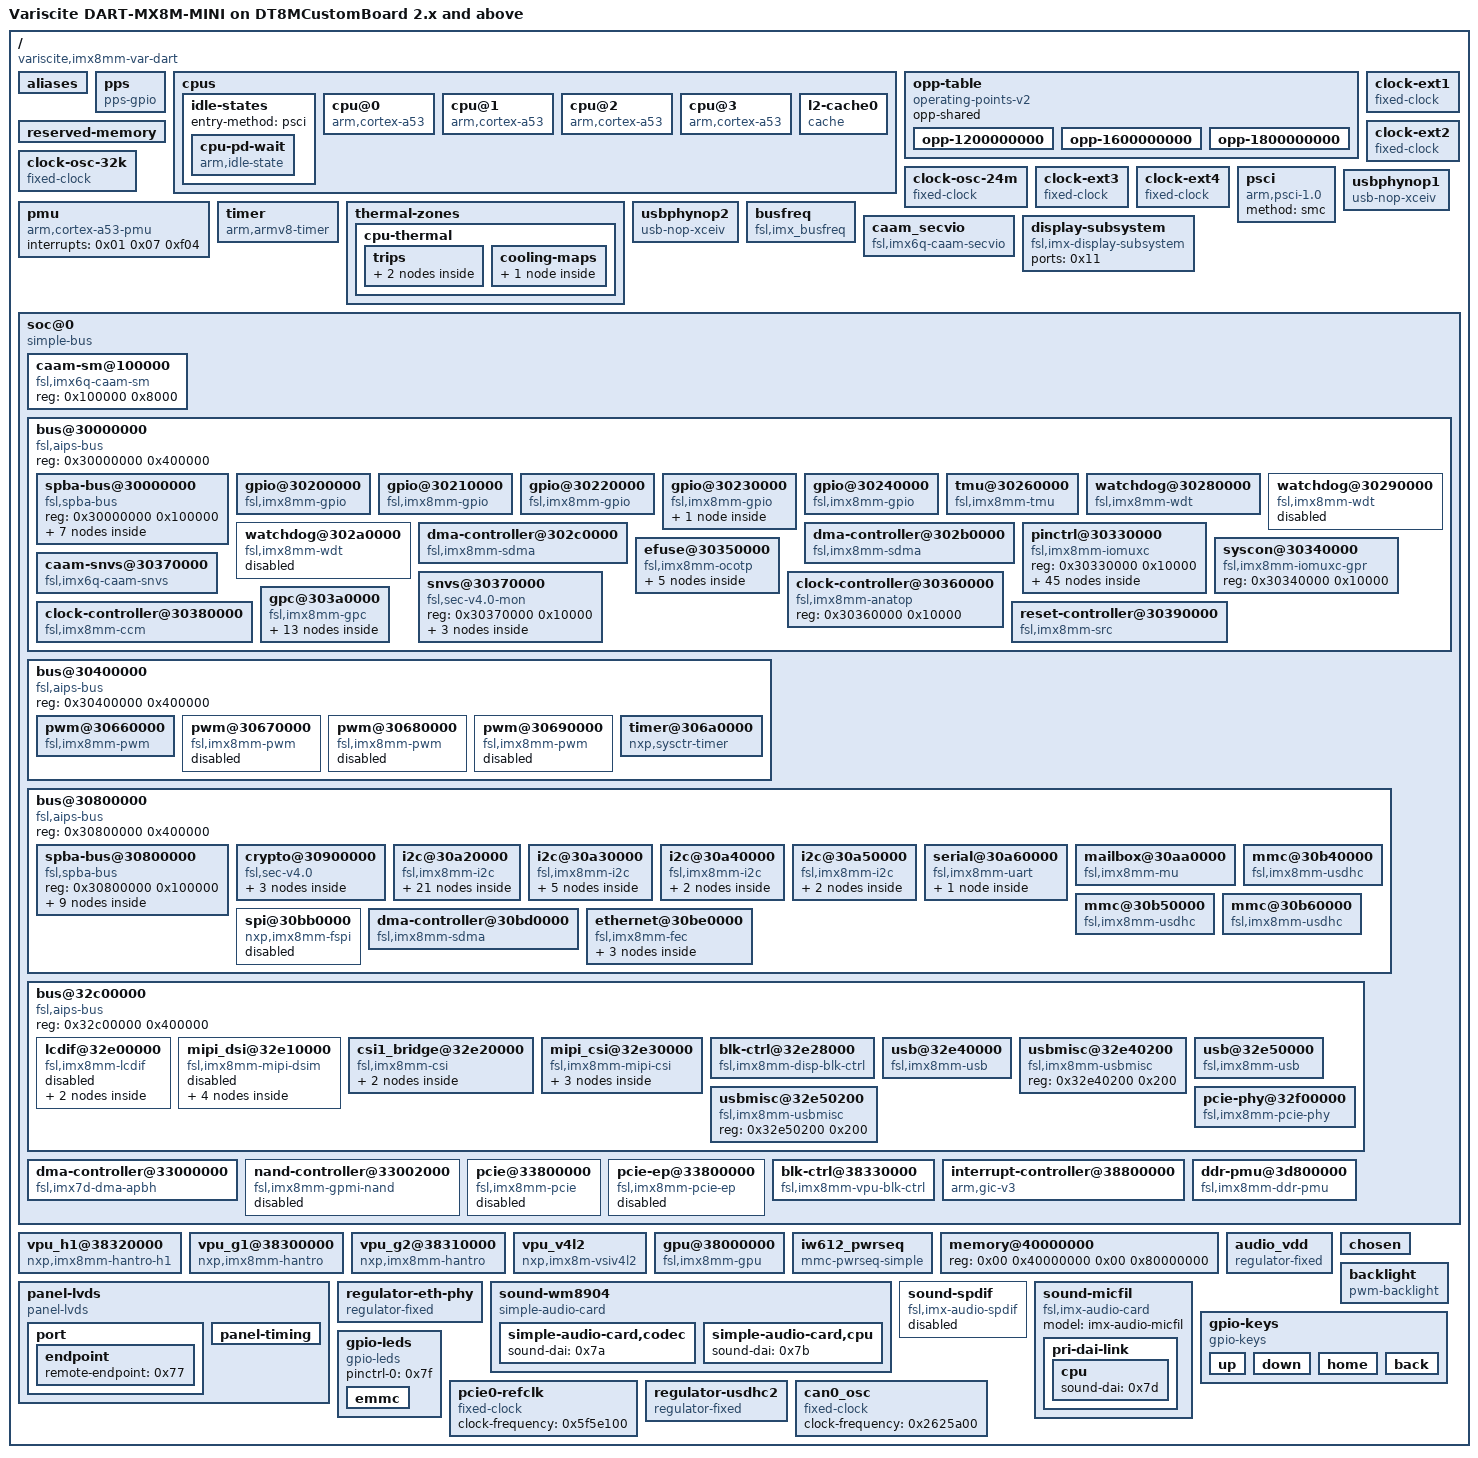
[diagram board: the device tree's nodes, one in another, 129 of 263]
/dts-v1/;

/ {
	interrupt-parent = <0x01>;
	#address-cells = <0x02>;
	#size-cells = <0x02>;
	compatible = "variscite,imx8mm-var-dart\0fsl,imx8mm";
	model = "Variscite DART-MX8M-MINI on DT8MCustomBoard 2.x and above";
	p1-version = "v1.0";

	aliases {
		ethernet0 = "/soc@0/bus@30800000/ethernet@30be0000";
		gpio0 = "/soc@0/bus@30000000/gpio@30200000";
		gpio1 = "/soc@0/bus@30000000/gpio@30210000";
		gpio2 = "/soc@0/bus@30000000/gpio@30220000";
		gpio3 = "/soc@0/bus@30000000/gpio@30230000";
		gpio4 = "/soc@0/bus@30000000/gpio@30240000";
		i2c0 = "/soc@0/bus@30800000/i2c@30a20000";
		i2c1 = "/soc@0/bus@30800000/i2c@30a30000";
		i2c2 = "/soc@0/bus@30800000/i2c@30a40000";
		i2c3 = "/soc@0/bus@30800000/i2c@30a50000";
		mmc0 = "/soc@0/bus@30800000/mmc@30b40000";
		mmc1 = "/soc@0/bus@30800000/mmc@30b50000";
		mmc2 = "/soc@0/bus@30800000/mmc@30b60000";
		sai1 = "/soc@0/bus@30000000/spba-bus@30000000/sai@30010000";
		sai2 = "/soc@0/bus@30000000/spba-bus@30000000/sai@30020000";
		sai3 = "/soc@0/bus@30000000/spba-bus@30000000/sai@30030000";
		sai5 = "/soc@0/bus@30000000/spba-bus@30000000/sai@30050000";
		sai6 = "/soc@0/bus@30000000/spba-bus@30000000/sai@30060000";
		serial0 = "/soc@0/bus@30800000/spba-bus@30800000/serial@30860000";
		serial1 = "/soc@0/bus@30800000/spba-bus@30800000/serial@30890000";
		serial2 = "/soc@0/bus@30800000/spba-bus@30800000/serial@30880000";
		serial3 = "/soc@0/bus@30800000/serial@30a60000";
		spi0 = "/soc@0/bus@30800000/spba-bus@30800000/spi@30820000";
		spi1 = "/soc@0/bus@30800000/spba-bus@30800000/spi@30830000";
		spi2 = "/soc@0/bus@30800000/spba-bus@30800000/spi@30840000";
	};

	pps {
		pinctrl-names = "default";
		pinctrl-0 = <0xd5>;
		compatible = "pps-gpio";
		gpios = <0x29 0x06 0x00>;
		status = "okay";
	};

	cpus {
		#address-cells = <0x01>;
		#size-cells = <0x00>;

		idle-states {
			entry-method = "psci";

			cpu-pd-wait {
				compatible = "arm,idle-state";
				arm,psci-suspend-param = <0x10033>;
				local-timer-stop;
				entry-latency-us = <0x3e8>;
				exit-latency-us = <0x2bc>;
				min-residency-us = <0xa8c>;
				phandle = <0x06>;
			};
		};

		cpu@0 {
			device_type = "cpu";
			compatible = "arm,cortex-a53";
			reg = <0x00>;
			clock-latency = <0xee6c>;
			clocks = <0x02 0xd7>;
			enable-method = "psci";
			i-cache-size = <0x8000>;
			i-cache-line-size = <0x40>;
			i-cache-sets = <0x100>;
			d-cache-size = <0x8000>;
			d-cache-line-size = <0x40>;
			d-cache-sets = <0x80>;
			next-level-cache = <0x03>;
			operating-points-v2 = <0x04>;
			nvmem-cells = <0x05>;
			nvmem-cell-names = "speed_grade";
			cpu-idle-states = <0x06>;
			#cooling-cells = <0x02>;
			cpu-supply = <0x07>;
			phandle = <0x0a>;
		};

		cpu@1 {
			device_type = "cpu";
			compatible = "arm,cortex-a53";
			reg = <0x01>;
			clock-latency = <0xee6c>;
			clocks = <0x02 0xd7>;
			enable-method = "psci";
			i-cache-size = <0x8000>;
			i-cache-line-size = <0x40>;
			i-cache-sets = <0x100>;
			d-cache-size = <0x8000>;
			d-cache-line-size = <0x40>;
			d-cache-sets = <0x80>;
			next-level-cache = <0x03>;
			operating-points-v2 = <0x04>;
			cpu-idle-states = <0x06>;
			#cooling-cells = <0x02>;
			cpu-supply = <0x07>;
			phandle = <0x0b>;
		};

		cpu@2 {
			device_type = "cpu";
			compatible = "arm,cortex-a53";
			reg = <0x02>;
			clock-latency = <0xee6c>;
			clocks = <0x02 0xd7>;
			enable-method = "psci";
			i-cache-size = <0x8000>;
			i-cache-line-size = <0x40>;
			i-cache-sets = <0x100>;
			d-cache-size = <0x8000>;
			d-cache-line-size = <0x40>;
			d-cache-sets = <0x80>;
			next-level-cache = <0x03>;
			operating-points-v2 = <0x04>;
			cpu-idle-states = <0x06>;
			#cooling-cells = <0x02>;
			cpu-supply = <0x07>;
			phandle = <0x0c>;
		};

		cpu@3 {
			device_type = "cpu";
			compatible = "arm,cortex-a53";
			reg = <0x03>;
			clock-latency = <0xee6c>;
			clocks = <0x02 0xd7>;
			enable-method = "psci";
			i-cache-size = <0x8000>;
			i-cache-line-size = <0x40>;
			i-cache-sets = <0x100>;
			d-cache-size = <0x8000>;
			d-cache-line-size = <0x40>;
			d-cache-sets = <0x80>;
			next-level-cache = <0x03>;
			operating-points-v2 = <0x04>;
			cpu-idle-states = <0x06>;
			#cooling-cells = <0x02>;
			cpu-supply = <0x07>;
			phandle = <0x0d>;
		};

		l2-cache0 {
			compatible = "cache";
			cache-level = <0x02>;
			cache-unified;
			cache-size = <0x80000>;
			cache-line-size = <0x40>;
			cache-sets = <0x200>;
			phandle = <0x03>;
		};
	};

	opp-table {
		compatible = "operating-points-v2";
		opp-shared;
		phandle = <0x04>;

		opp-1200000000 {
			opp-hz = <0x00 0x47868c00>;
			opp-microvolt = <0xcf850>;
			opp-supported-hw = <0x0e 0x07>;
			clock-latency-ns = <0x249f0>;
			opp-suspend;
		};

		opp-1600000000 {
			opp-hz = <0x00 0x5f5e1000>;
			opp-microvolt = <0xe7ef0>;
			opp-supported-hw = <0x0c 0x07>;
			clock-latency-ns = <0x249f0>;
			opp-suspend;
		};

		opp-1800000000 {
			opp-hz = <0x00 0x6b49d200>;
			opp-microvolt = <0xf4240>;
			opp-supported-hw = <0x08 0x03>;
			clock-latency-ns = <0x249f0>;
			opp-suspend;
		};
	};

	reserved-memory {
		#address-cells = <0x02>;
		#size-cells = <0x02>;
		ranges;
		phandle = <0x81>;
	};

	clock-osc-32k {
		compatible = "fixed-clock";
		#clock-cells = <0x00>;
		clock-frequency = <0x8000>;
		clock-output-names = "osc_32k";
		phandle = <0x1c>;
	};

	clock-osc-24m {
		compatible = "fixed-clock";
		#clock-cells = <0x00>;
		clock-frequency = <0x16e3600>;
		clock-output-names = "osc_24m";
		phandle = <0x1d>;
	};

	clock-ext1 {
		compatible = "fixed-clock";
		#clock-cells = <0x00>;
		clock-frequency = <0x7ed6b40>;
		clock-output-names = "clk_ext1";
		phandle = <0x1e>;
	};

	clock-ext2 {
		compatible = "fixed-clock";
		#clock-cells = <0x00>;
		clock-frequency = <0x7ed6b40>;
		clock-output-names = "clk_ext2";
		phandle = <0x1f>;
	};

	clock-ext3 {
		compatible = "fixed-clock";
		#clock-cells = <0x00>;
		clock-frequency = <0x7ed6b40>;
		clock-output-names = "clk_ext3";
		phandle = <0x20>;
	};

	clock-ext4 {
		compatible = "fixed-clock";
		#clock-cells = <0x00>;
		clock-frequency = <0x7ed6b40>;
		clock-output-names = "clk_ext4";
		phandle = <0x21>;
	};

	psci {
		compatible = "arm,psci-1.0";
		method = "smc";
	};

	pmu {
		compatible = "arm,cortex-a53-pmu";
		interrupts = <0x01 0x07 0xf04>;
	};

	timer {
		compatible = "arm,armv8-timer";
		interrupts = <0x01 0x0d 0xf08 0x01 0x0e 0xf08 0x01 0x0b 0xf08 0x01 0x0a 0xf08>;
		clock-frequency = <0x7a1200>;
		arm,no-tick-in-suspend;
	};

	thermal-zones {

		cpu-thermal {
			polling-delay-passive = <0xfa>;
			polling-delay = <0x7d0>;
			thermal-sensors = <0x08>;

			trips {

				trip0 {
					temperature = <0x14c08>;
					hysteresis = <0x7d0>;
					type = "passive";
					phandle = <0x09>;
				};

				trip1 {
					temperature = <0x17318>;
					hysteresis = <0x7d0>;
					type = "critical";
					phandle = <0x82>;
				};
			};

			cooling-maps {

				map0 {
					trip = <0x09>;
					cooling-device = <0x0a 0xffffffff 0xffffffff 0x0b 0xffffffff 0xffffffff 0x0c 0xffffffff 0xffffffff 0x0d 0xffffffff 0xffffffff 0x0e 0x00 0x01>;
				};
			};
		};
	};

	usbphynop1 {
		#phy-cells = <0x00>;
		compatible = "usb-nop-xceiv";
		clocks = <0x02 0x84>;
		assigned-clocks = <0x02 0x84>;
		assigned-clock-parents = <0x02 0x32>;
		clock-names = "main_clk";
		power-domains = <0x0f>;
		wakeup-source;
		phandle = <0x67>;
	};

	usbphynop2 {
		#phy-cells = <0x00>;
		compatible = "usb-nop-xceiv";
		clocks = <0x02 0x84>;
		assigned-clocks = <0x02 0x84>;
		assigned-clock-parents = <0x02 0x32>;
		clock-names = "main_clk";
		power-domains = <0x10>;
		wakeup-source;
		phandle = <0x6a>;
	};

	busfreq {
		compatible = "fsl,imx_busfreq";
		clocks = <0x02 0x29 0x02 0x61 0x02 0x62 0x02 0x62 0x02 0xdc 0x02 0xdd 0x02 0x30 0x02 0x32 0x02 0x3f 0x02 0x5b 0x02 0x5d 0x02 0x51 0x02 0x02 0x02 0x38 0x02 0x15>;
		clock-names = "dram_pll\0dram_alt_src\0dram_apb_src\0dram_apb_pre_div\0dram_core\0dram_alt_root\0sys_pll1_40m\0sys_pll1_100m\0sys_pll2_333m\0noc_div\0ahb_div\0main_axi_src\0osc_24m\0sys_pll1_800m\0dram_pll_div";
		interrupts = <0x00 0x4a 0x04 0x00 0x4b 0x04 0x00 0x4c 0x04 0x00 0x4d 0x04>;
		interrupt-name = "irq_busfreq_0\0irq_busfreq_1\0irq_busfreq_2\0irq_busfreq_3";
	};

	caam_secvio {
		compatible = "fsl,imx6q-caam-secvio";
		interrupts = <0x00 0x14 0x04>;
		jtag-tamper = "disabled";
		watchdog-tamper = "enabled";
		internal-boot-tamper = "enabled";
		external-pin-tamper = "disabled";
		phandle = <0x83>;
	};

	display-subsystem {
		compatible = "fsl,imx-display-subsystem";
		ports = <0x11>;
	};

	soc@0 {
		compatible = "simple-bus";
		#address-cells = <0x01>;
		#size-cells = <0x01>;
		ranges = <0x00 0x00 0x00 0x3e000000>;
		dma-ranges = <0x40000000 0x00 0x40000000 0xc0000000>;
		nvmem-cells = <0x12>;
		nvmem-cell-names = "soc_unique_id";
		phandle = <0x84>;

		caam-sm@100000 {
			compatible = "fsl,imx6q-caam-sm";
			reg = <0x100000 0x8000>;
			phandle = <0x85>;
		};

		bus@30000000 {
			compatible = "fsl,aips-bus\0simple-bus";
			reg = <0x30000000 0x400000>;
			#address-cells = <0x01>;
			#size-cells = <0x01>;
			ranges = <0x30000000 0x30000000 0x400000>;
			phandle = <0x86>;

			spba-bus@30000000 {
				compatible = "fsl,spba-bus\0simple-bus";
				#address-cells = <0x01>;
				#size-cells = <0x01>;
				reg = <0x30000000 0x100000>;
				ranges;
				phandle = <0x87>;

				sai@30010000 {
					#sound-dai-cells = <0x00>;
					compatible = "fsl,imx8mm-sai\0fsl,imx8mq-sai";
					reg = <0x30010000 0x10000>;
					interrupts = <0x00 0x5f 0x04>;
					clocks = <0x02 0xb1 0x02 0x00 0x02 0xb0 0x02 0x00 0x02 0x00>;
					clock-names = "bus\0mclk0\0mclk1\0mclk2\0mclk3";
					dmas = <0x13 0x00 0x02 0x00 0x13 0x01 0x02 0x00>;
					dma-names = "rx\0tx";
					fsl,dataline = <0x00 0xff 0xff>;
					status = "disabled";
					phandle = <0x88>;
				};

				sai@30020000 {
					#sound-dai-cells = <0x00>;
					compatible = "fsl,imx8mm-sai\0fsl,imx8mq-sai";
					reg = <0x30020000 0x10000>;
					interrupts = <0x00 0x60 0x04>;
					clocks = <0x02 0xb3 0x02 0x00 0x02 0xb2 0x02 0x00 0x02 0x00>;
					clock-names = "bus\0mclk0\0mclk1\0mclk2\0mclk3";
					dmas = <0x13 0x02 0x02 0x00 0x13 0x03 0x02 0x00>;
					dma-names = "rx\0tx";
					status = "disabled";
					phandle = <0x89>;
				};

				sai@30030000 {
					#sound-dai-cells = <0x00>;
					compatible = "fsl,imx8mm-sai\0fsl,imx8mq-sai";
					reg = <0x30030000 0x10000>;
					interrupts = <0x00 0x32 0x04>;
					clocks = <0x02 0xb5 0x02 0x00 0x02 0xb4 0x02 0x00 0x02 0x00>;
					clock-names = "bus\0mclk0\0mclk1\0mclk2\0mclk3";
					dmas = <0x13 0x04 0x02 0x00 0x13 0x05 0x02 0x00>;
					dma-names = "rx\0tx";
					status = "okay";
					pinctrl-names = "default";
					pinctrl-0 = <0x14>;
					assigned-clocks = <0x02 0x6e>;
					assigned-clock-parents = <0x02 0x26>;
					assigned-clock-rates = <0x177000>;
					fsl,sai-mclk-direction-output;
					fsl,sai-synchronous-rx;
					phandle = <0x7b>;
				};

				sai@30050000 {
					#sound-dai-cells = <0x00>;
					compatible = "fsl,imx8mm-sai\0fsl,imx8mq-sai";
					reg = <0x30050000 0x10000>;
					interrupts = <0x00 0x5a 0x04>;
					clocks = <0x02 0xb9 0x02 0x00 0x02 0xb8 0x02 0x00 0x02 0x00>;
					clock-names = "bus\0mclk0\0mclk1\0mclk2\0mclk3";
					dmas = <0x13 0x08 0x02 0x00 0x13 0x09 0x02 0x00>;
					dma-names = "rx\0tx";
					fsl,dataline = <0x00 0x0f 0x0f>;
					status = "disabled";
					phandle = <0x8a>;
				};

				sai@30060000 {
					#sound-dai-cells = <0x00>;
					compatible = "fsl,imx8mm-sai\0fsl,imx8mq-sai";
					reg = <0x30060000 0x10000>;
					interrupts = <0x00 0x5a 0x04>;
					clocks = <0x02 0xbb 0x02 0x00 0x02 0xba 0x02 0x00 0x02 0x00>;
					clock-names = "bus\0mclk0\0mclk1\0mclk2\0mclk3";
					dmas = <0x13 0x0a 0x02 0x00 0x13 0x0b 0x02 0x00>;
					dma-names = "rx\0tx";
					status = "disabled";
					phandle = <0x8b>;
				};

				audio-controller@30080000 {
					compatible = "fsl,imx8mm-micfil";
					reg = <0x30080000 0x10000>;
					interrupts = <0x00 0x6d 0x04 0x00 0x6e 0x04 0x00 0x2c 0x04 0x00 0x2d 0x04>;
					clocks = <0x02 0xd8 0x02 0xcb 0x02 0x26 0x02 0x27 0x02 0x06>;
					clock-names = "ipg_clk\0ipg_clk_app\0pll8k\0pll11k\0clkext3";
					dmas = <0x13 0x18 0x19 0x80000000>;
					dma-names = "rx";
					#sound-dai-cells = <0x00>;
					status = "disabled";
					pinctrl-names = "default";
					pinctrl-0 = <0x15>;
					assigned-clocks = <0x02 0x9c>;
					assigned-clock-parents = <0x02 0x26>;
					assigned-clock-rates = <0xbb80000>;
					phandle = <0x7d>;
				};

				spdif@30090000 {
					compatible = "fsl,imx35-spdif";
					reg = <0x30090000 0x10000>;
					interrupts = <0x00 0x06 0x04>;
					clocks = <0x02 0x5e 0x02 0x02 0x02 0x72 0x02 0x00 0x02 0x00 0x02 0x00 0x02 0x5e 0x02 0x00 0x02 0x00 0x02 0x00 0x02 0x26 0x02 0x27>;
					clock-names = "core\0rxtx0\0rxtx1\0rxtx2\0rxtx3\0rxtx4\0rxtx5\0rxtx6\0rxtx7\0spba\0pll8k\0pll11k";
					dmas = <0x13 0x1c 0x12 0x00 0x13 0x1d 0x12 0x00>;
					dma-names = "rx\0tx";
					status = "disabled";
					pinctrl-names = "default";
					pinctrl-0 = <0x16>;
					assigned-clocks = <0x02 0x72>;
					assigned-clock-parents = <0x02 0x26>;
					assigned-clock-rates = <0x1770000>;
					phandle = <0x7c>;
				};
			};

			gpio@30200000 {
				compatible = "fsl,imx8mm-gpio\0fsl,imx35-gpio";
				reg = <0x30200000 0x10000>;
				interrupts = <0x00 0x40 0x04 0x00 0x41 0x04>;
				clocks = <0x02 0xdf>;
				gpio-controller;
				#gpio-cells = <0x02>;
				interrupt-controller;
				#interrupt-cells = <0x02>;
				gpio-ranges = <0x17 0x00 0x0a 0x1e>;
				phandle = <0x29>;
			};

			gpio@30210000 {
				compatible = "fsl,imx8mm-gpio\0fsl,imx35-gpio";
				reg = <0x30210000 0x10000>;
				interrupts = <0x00 0x42 0x04 0x00 0x43 0x04>;
				clocks = <0x02 0xe0>;
				gpio-controller;
				#gpio-cells = <0x02>;
				interrupt-controller;
				#interrupt-cells = <0x02>;
				gpio-ranges = <0x17 0x00 0x28 0x15>;
				phandle = <0x32>;
			};

			gpio@30220000 {
				compatible = "fsl,imx8mm-gpio\0fsl,imx35-gpio";
				reg = <0x30220000 0x10000>;
				interrupts = <0x00 0x44 0x04 0x00 0x45 0x04>;
				clocks = <0x02 0xe1>;
				gpio-controller;
				#gpio-cells = <0x02>;
				interrupt-controller;
				#interrupt-cells = <0x02>;
				gpio-ranges = <0x17 0x00 0x3d 0x1a>;
				phandle = <0x8c>;
			};

			gpio@30230000 {
				compatible = "fsl,imx8mm-gpio\0fsl,imx35-gpio";
				reg = <0x30230000 0x10000>;
				interrupts = <0x00 0x46 0x04 0x00 0x47 0x04>;
				clocks = <0x02 0xe2>;
				gpio-controller;
				#gpio-cells = <0x02>;
				interrupt-controller;
				#interrupt-cells = <0x02>;
				gpio-ranges = <0x17 0x00 0x57 0x20>;
				pinctrl-names = "default";
				pinctrl-0 = <0x18>;
				phandle = <0x2a>;

				sec_rstn {
					gpio-hog;
					gpios = <0x1f 0x00>;
					output-high;
					line-name = "sec_rstn";
				};
			};

			gpio@30240000 {
				compatible = "fsl,imx8mm-gpio\0fsl,imx35-gpio";
				reg = <0x30240000 0x10000>;
				interrupts = <0x00 0x48 0x04 0x00 0x49 0x04>;
				clocks = <0x02 0xe3>;
				gpio-controller;
				#gpio-cells = <0x02>;
				interrupt-controller;
				#interrupt-cells = <0x02>;
				gpio-ranges = <0x17 0x00 0x77 0x1e>;
				phandle = <0x28>;
			};

			tmu@30260000 {
				compatible = "fsl,imx8mm-tmu";
				reg = <0x30260000 0x10000>;
				clocks = <0x02 0xd1>;
				nvmem-cells = <0x19>;
				nvmem-cell-names = "calib";
				#thermal-sensor-cells = <0x00>;
				phandle = <0x08>;
			};

			watchdog@30280000 {
				compatible = "fsl,imx8mm-wdt\0fsl,imx21-wdt";
				reg = <0x30280000 0x10000>;
				interrupts = <0x00 0x4e 0x04>;
				clocks = <0x02 0xc4>;
				status = "okay";
				pinctrl-names = "default";
				pinctrl-0 = <0x1a>;
				fsl,ext-reset-output;
				phandle = <0x8d>;
			};

			watchdog@30290000 {
				compatible = "fsl,imx8mm-wdt\0fsl,imx21-wdt";
				reg = <0x30290000 0x10000>;
				interrupts = <0x00 0x4f 0x04>;
				clocks = <0x02 0xc5>;
				status = "disabled";
				phandle = <0x8e>;
			};

			watchdog@302a0000 {
				compatible = "fsl,imx8mm-wdt\0fsl,imx21-wdt";
				reg = <0x302a0000 0x10000>;
				interrupts = <0x00 0x0a 0x04>;
				clocks = <0x02 0xc6>;
				status = "disabled";
				phandle = <0x8f>;
			};

			dma-controller@302c0000 {
				compatible = "fsl,imx8mm-sdma\0fsl,imx8mq-sdma";
				reg = <0x302c0000 0x10000>;
				interrupts = <0x00 0x67 0x04>;
				clocks = <0x02 0xd4 0x02 0xd4>;
				clock-names = "ipg\0ahb";
				#dma-cells = <0x03>;
				fsl,sdma-ram-script-name = "imx/sdma/sdma-imx7d.bin";
				phandle = <0x13>;
			};

			dma-controller@302b0000 {
				compatible = "fsl,imx8mm-sdma\0fsl,imx8mq-sdma";
				reg = <0x302b0000 0x10000>;
				interrupts = <0x00 0x22 0x04>;
				clocks = <0x02 0xd5 0x02 0xd5>;
				clock-names = "ipg\0ahb";
				#dma-cells = <0x03>;
				fsl,sdma-ram-script-name = "imx/sdma/sdma-imx7d.bin";
				phandle = <0x90>;
			};

			pinctrl@30330000 {
				compatible = "fsl,imx8mm-iomuxc";
				reg = <0x30330000 0x10000>;
				phandle = <0x17>;

				fec1grp {
					fsl,pins = <0x68 0x2d0 0x00 0x00 0x00 0x03 0x6c 0x2d4 0x4c0 0x00 0x01 0x03 0x70 0x2d8 0x00 0x00 0x00 0x1f 0x74 0x2dc 0x00 0x00 0x00 0x1f 0x78 0x2e0 0x00 0x00 0x00 0x1f 0x7c 0x2e4 0x00 0x00 0x00 0x1f 0x9c 0x304 0x00 0x00 0x00 0x91 0x98 0x300 0x00 0x00 0x00 0x91 0x94 0x2fc 0x00 0x00 0x00 0x91 0x90 0x2f8 0x00 0x00 0x00 0x91 0x84 0x2ec 0x00 0x00 0x00 0x1f 0x8c 0x2f4 0x00 0x00 0x00 0x91 0x88 0x2f0 0x00 0x00 0x00 0x91 0x80 0x2e8 0x00 0x00 0x00 0x1f 0x4c 0x2b4 0x00 0x00 0x00 0x19>;
					phandle = <0x59>;
				};

				fec1grpsleep {
					fsl,pins = <0x68 0x2d0 0x00 0x05 0x00 0x120 0x6c 0x2d4 0x00 0x05 0x00 0x120 0x70 0x2d8 0x00 0x05 0x00 0x120 0x74 0x2dc 0x00 0x05 0x00 0x120 0x78 0x2e0 0x00 0x05 0x00 0x120 0x7c 0x2e4 0x00 0x05 0x00 0x120 0x9c 0x304 0x00 0x05 0x00 0x120 0x98 0x300 0x00 0x05 0x00 0x120 0x94 0x2fc 0x00 0x05 0x00 0x120 0x90 0x2f8 0x00 0x05 0x00 0x120 0x84 0x2ec 0x00 0x05 0x00 0x120 0x8c 0x2f4 0x00 0x05 0x00 0x120 0x88 0x2f0 0x00 0x05 0x00 0x120 0x80 0x2e8 0x00 0x05 0x00 0x120 0x4c 0x2b4 0x00 0x00 0x00 0x100>;
					phandle = <0x5a>;
				};

				i2c1grp {
					fsl,pins = <0x214 0x47c 0x00 0x00 0x00 0x400001c3 0x218 0x480 0x00 0x00 0x00 0x400001c3>;
					phandle = <0x30>;
				};

				tpm-resetgrp {
					fsl,pins = <0x1d8 0x440 0x00 0x05 0x00 0x19>;
					phandle = <0x18>;
				};

				i2c3grp {
					fsl,pins = <0x224 0x48c 0x00 0x00 0x00 0x400001c3 0x228 0x490 0x00 0x00 0x00 0x400001c3>;
					phandle = <0x40>;
				};

				i2c1grp-gpio {
					fsl,pins = <0x214 0x47c 0x00 0x05 0x00 0x1c3 0x218 0x480 0x00 0x05 0x00 0x1c3>;
					phandle = <0x31>;
				};

				i2c3grp-gpio {
					fsl,pins = <0x224 0x48c 0x00 0x05 0x00 0x1c3 0x228 0x490 0x00 0x05 0x00 0x1c3>;
					phandle = <0x41>;
				};

				lvdsgrp {
					fsl,pins = <0xcc 0x334 0x00 0x05 0x00 0x16>;
					phandle = <0x33>;
				};

				pmicgrp {
					fsl,pins = <0xc0 0x328 0x00 0x05 0x00 0x140>;
					phandle = <0x36>;
				};

				regethphy {
					fsl,pins = <0x44 0x2ac 0x00 0x00 0x00 0x41>;
					phandle = <0x78>;
				};

				sai3grp {
					fsl,pins = <0x1cc 0x434 0x00 0x00 0x00 0xd6 0x1d0 0x438 0x00 0x00 0x00 0xd6 0x1d4 0x43c 0x00 0x00 0x00 0xd6 0x1e0 0x448 0x00 0x00 0x00 0xd6 0x1e4 0x44c 0x00 0x00 0x00 0xd6>;
					phandle = <0x14>;
				};

				spdif1grp {
					fsl,pins = <0x1e8 0x450 0x00 0x00 0x00 0xd6 0x1ec 0x454 0x00 0x00 0x00 0xd6>;
					phandle = <0x16>;
				};

				uart4grp {
					fsl,pins = <0x204 0x46c 0x50c 0x01 0x00 0x140 0x208 0x470 0x00 0x01 0x00 0x140 0x210 0x478 0x508 0x01 0x01 0x140 0x20c 0x474 0x00 0x01 0x00 0x140>;
					phandle = <0x47>;
				};

				usdhc1grp {
					fsl,pins = <0xa0 0x308 0x00 0x00 0x00 0x190 0xa4 0x30c 0x00 0x00 0x00 0x1d0 0xa8 0x310 0x00 0x00 0x00 0x1d0 0xac 0x314 0x00 0x00 0x00 0x1d0 0xb0 0x318 0x00 0x00 0x00 0x1d0 0xb4 0x31c 0x00 0x00 0x00 0x1d0>;
					phandle = <0x49>;
				};

				usdhc1grp100mhz {
					fsl,pins = <0xa0 0x308 0x00 0x00 0x00 0x194 0xa4 0x30c 0x00 0x00 0x00 0x1d4 0xa8 0x310 0x00 0x00 0x00 0x1d4 0xac 0x314 0x00 0x00 0x00 0x1d4 0xb0 0x318 0x00 0x00 0x00 0x1d4 0xb4 0x31c 0x00 0x00 0x00 0x1d4>;
					phandle = <0x4b>;
				};

				usdhc1grp200mhz {
					fsl,pins = <0xa0 0x308 0x00 0x00 0x00 0x196 0xa4 0x30c 0x00 0x00 0x00 0x1d6 0xa8 0x310 0x00 0x00 0x00 0x1d6 0xac 0x314 0x00 0x00 0x00 0x1d6 0xb0 0x318 0x00 0x00 0x00 0x1d6 0xb4 0x31c 0x00 0x00 0x00 0x1d6>;
					phandle = <0x4c>;
				};

				usdhc3grp {
					fsl,pins = <0x138 0x3a0 0x00 0x12 0x00 0x190 0x13c 0x3a4 0x00 0x02 0x00 0x1d0 0x11c 0x384 0x00 0x02 0x00 0x1d0 0x120 0x388 0x00 0x02 0x00 0x1d0 0x124 0x38c 0x00 0x02 0x00 0x1d0 0x128 0x390 0x00 0x02 0x00 0x1d0 0x130 0x398 0x00 0x02 0x00 0x1d0 0x100 0x368 0x00 0x02 0x00 0x1d0 0x104 0x36c 0x00 0x02 0x00 0x1d0 0x108 0x370 0x00 0x02 0x00 0x1d0 0xfc 0x364 0x00 0x02 0x00 0x190>;
					phandle = <0x53>;
				};

				usdhc3grp100mhz {
					fsl,pins = <0x138 0x3a0 0x00 0x12 0x00 0x194 0x13c 0x3a4 0x00 0x02 0x00 0x1d4 0x11c 0x384 0x00 0x02 0x00 0x1d4 0x120 0x388 0x00 0x02 0x00 0x1d4 0x124 0x38c 0x00 0x02 0x00 0x1d4 0x128 0x390 0x00 0x02 0x00 0x1d4 0x130 0x398 0x00 0x02 0x00 0x1d4 0x100 0x368 0x00 0x02 0x00 0x1d4 0x104 0x36c 0x00 0x02 0x00 0x1d4 0x108 0x370 0x00 0x02 0x00 0x1d4 0xfc 0x364 0x00 0x02 0x00 0x194>;
					phandle = <0x54>;
				};

				usdhc3grp200mhz {
					fsl,pins = <0x138 0x3a0 0x00 0x12 0x00 0x196 0x13c 0x3a4 0x00 0x02 0x00 0x1d6 0x11c 0x384 0x00 0x02 0x00 0x1d6 0x120 0x388 0x00 0x02 0x00 0x1d6 0x124 0x38c 0x00 0x02 0x00 0x1d6 0x128 0x390 0x00 0x02 0x00 0x1d6 0x130 0x398 0x00 0x02 0x00 0x1d6 0x100 0x368 0x00 0x02 0x00 0x1d6 0x104 0x36c 0x00 0x02 0x00 0x1d6 0x108 0x370 0x00 0x02 0x00 0x1d6 0xfc 0x364 0x00 0x02 0x00 0x196>;
					phandle = <0x55>;
				};

				wdoggrp {
					fsl,pins = <0x30 0x298 0x00 0x01 0x00 0xc6>;
					phandle = <0x1a>;
				};

				wifigrp {
					fsl,pins = <0xf0 0x358 0x00 0x05 0x00 0x140 0xc8 0x330 0x00 0x05 0x00 0xc1>;
					phandle = <0x4a>;
				};

				btgrp {
					fsl,pins = <0xb8 0x320 0x00 0x05 0x00 0xc1 0x1f0 0x458 0x00 0x05 0x00 0xc1>;
					phandle = <0x48>;
				};

				flexspi0grp {
					fsl,pins = <0xf4 0x35c 0x00 0x01 0x00 0x1c2 0xf8 0x360 0x00 0x01 0x00 0x82 0x10c 0x374 0x00 0x01 0x00 0x82 0x110 0x378 0x00 0x01 0x00 0x82 0x114 0x37c 0x00 0x01 0x00 0x82 0x118 0x380 0x00 0x01 0x00 0x82>;
					phandle = <0x56>;
				};

				pdmgrp {
					fsl,pins = <0x158 0x3c0 0x52c 0x00 0x00 0xd6 0x144 0x3ac 0x00 0x04 0x00 0xd6 0x140 0x3a8 0x4e4 0x00 0x00 0xd6 0x148 0x3b0 0x534 0x04 0x00 0xd6 0x14c 0x3b4 0x538 0x04 0x00 0xd6 0x150 0x3b8 0x53c 0x04 0x00 0xd6 0x154 0x3bc 0x540 0x04 0x00 0xd6>;
					phandle = <0x15>;
				};

				i2c2grp {
					fsl,pins = <0x21c 0x484 0x00 0x00 0x00 0x400001c3 0x220 0x488 0x00 0x00 0x00 0x400001c3>;
					phandle = <0x37>;
				};

				i2c2grp-gpio {
					fsl,pins = <0x21c 0x484 0x00 0x05 0x00 0x1c3 0x220 0x488 0x00 0x05 0x00 0x1c3>;
					phandle = <0x38>;
				};

				i2c4grp {
					fsl,pins = <0x22c 0x494 0x00 0x00 0x00 0x400001c3 0x230 0x498 0x00 0x00 0x00 0x400001c3>;
					phandle = <0x44>;
				};

				i2c4grp-gpio {
					fsl,pins = <0x22c 0x494 0x00 0x05 0x00 0x1c3 0x230 0x498 0x00 0x05 0x00 0x1c3>;
					phandle = <0x45>;
				};

				uart1grp {
					fsl,pins = <0x234 0x49c 0x4f4 0x00 0x00 0x140 0x238 0x4a0 0x00 0x00 0x00 0x140>;
					phandle = <0x2d>;
				};

				uart2grp {
					fsl,pins = <0x23c 0x4a4 0x4fc 0x00 0x00 0x140 0x240 0x4a8 0x00 0x00 0x00 0x140>;
					phandle = <0x2f>;
				};

				uart3grp {
					fsl,pins = <0x244 0x4ac 0x504 0x00 0x02 0x140 0x248 0x4b0 0x00 0x00 0x00 0x140>;
					phandle = <0x2e>;
				};

				regusdhc2vmmc {
					fsl,pins = <0xec 0x354 0x00 0x05 0x00 0xc1>;
					phandle = <0x80>;
				};

				usdhc2grpgpio {
					fsl,pins = <0xd0 0x338 0x00 0x05 0x00 0xc1>;
					phandle = <0x4f>;
				};

				usdhc2grp {
					fsl,pins = <0xd4 0x33c 0x00 0x00 0x00 0x190 0xd8 0x340 0x00 0x00 0x00 0x1d0 0xdc 0x344 0x00 0x00 0x00 0x1d0 0xe0 0x348 0x00 0x00 0x00 0x1d0 0xe4 0x34c 0x00 0x00 0x00 0x1d0 0xe8 0x350 0x00 0x00 0x00 0x1d0 0x38 0x2a0 0x00 0x01 0x00 0x1d0>;
					phandle = <0x4e>;
				};

				usdhc2grp100mhz {
					fsl,pins = <0xd4 0x33c 0x00 0x00 0x00 0x194 0xd8 0x340 0x00 0x00 0x00 0x1d4 0xdc 0x344 0x00 0x00 0x00 0x1d4 0xe0 0x348 0x00 0x00 0x00 0x1d4 0xe4 0x34c 0x00 0x00 0x00 0x1d4 0xe8 0x350 0x00 0x00 0x00 0x1d4 0x38 0x2a0 0x00 0x01 0x00 0x1d0>;
					phandle = <0x50>;
				};

				usdhc2grp200mhz {
					fsl,pins = <0xd4 0x33c 0x00 0x00 0x00 0x196 0xd8 0x340 0x00 0x00 0x00 0x1d6 0xdc 0x344 0x00 0x00 0x00 0x1d6 0xe0 0x348 0x00 0x00 0x00 0x1d6 0xe4 0x34c 0x00 0x00 0x00 0x1d6 0xe8 0x350 0x00 0x00 0x00 0x1d6 0x38 0x2a0 0x00 0x01 0x00 0x1d0>;
					phandle = <0x51>;
				};

				backlightgrp {
					fsl,pins = <0x2c 0x294 0x00 0x01 0x00 0x06>;
					phandle = <0x25>;
				};

				captouchgrp {
					fsl,pins = <0x60 0x2c8 0x00 0x00 0x00 0x16>;
					phandle = <0x3b>;
				};

				extcongrp {
					fsl,pins = <0x50 0x2b8 0x00 0x00 0x00 0x19>;
					phandle = <0x39>;
				};

				ecspi1grp {
					fsl,pins = <0x1f4 0x45c 0x00 0x00 0x00 0x13 0x1f8 0x460 0x00 0x00 0x00 0x13 0x1fc 0x464 0x00 0x00 0x00 0x13 0x200 0x468 0x00 0x05 0x00 0x13 0x58 0x2c0 0x00 0x00 0x00 0x13 0x1b4 0x41c 0x00 0x05 0x00 0x13>;
					phandle = <0x27>;
				};

				cangrp {
					fsl,pins = <0x40 0x2a8 0x00 0x00 0x00 0x16 0x1ec 0x454 0x00 0x05 0x00 0x16>;
					phandle = <0x2b>;
				};

				ledgrp {
					fsl,pins = <0x1a4 0x40c 0x00 0x05 0x00 0x1c6>;
					phandle = <0x7f>;
				};

				pca6408grp {
					fsl,pins = <0x3c 0x2a4 0x00 0x00 0x00 0x1c6>;
					phandle = <0x46>;
				};

				rtcgrp {
					fsl,pins = <0x34 0x29c 0x00 0x00 0x00 0x1c1>;
					phandle = <0x3f>;
				};

				ppsgrp {
					fsl,pins = <0x40 0x2a8 0x00 0x00 0x00 0x19>;
					phandle = <0xd5>;
				};
			};

			syscon@30340000 {
				compatible = "fsl,imx8mm-iomuxc-gpr\0syscon";
				reg = <0x30340000 0x10000>;
				phandle = <0x58>;
			};

			efuse@30350000 {
				compatible = "fsl,imx8mm-ocotp\0syscon\0simple-mfd";
				reg = <0x30350000 0x10000>;
				clocks = <0x02 0xa8>;
				#address-cells = <0x01>;
				#size-cells = <0x01>;
				phandle = <0x92>;

				unique-id@4 {
					reg = <0x04 0x08>;
					phandle = <0x12>;
				};

				speed-grade@10 {
					reg = <0x10 0x04>;
					phandle = <0x05>;
				};

				calib@3c {
					reg = <0x3c 0x04>;
					phandle = <0x19>;
				};

				mac-address@90 {
					reg = <0x90 0x06>;
					phandle = <0x57>;
				};

				imx8mm-soc {
					compatible = "fsl,imx8mm-soc";
					nvmem-cells = <0x12>;
					nvmem-cell-names = "soc_unique_id";
					phandle = <0x93>;
				};
			};

			clock-controller@30360000 {
				compatible = "fsl,imx8mm-anatop";
				reg = <0x30360000 0x10000>;
				#clock-cells = <0x01>;
				phandle = <0x94>;
			};

			caam-snvs@30370000 {
				compatible = "fsl,imx6q-caam-snvs";
				reg = <0x30370000 0x10000>;
				clocks = <0x02 0xe4>;
				clock-names = "ipg";
				phandle = <0x95>;
			};

			snvs@30370000 {
				compatible = "fsl,sec-v4.0-mon\0syscon\0simple-mfd";
				reg = <0x30370000 0x10000>;
				phandle = <0x1b>;

				snvs-rtc-lp {
					compatible = "fsl,sec-v4.0-mon-rtc-lp";
					regmap = <0x1b>;
					offset = <0x34>;
					interrupts = <0x00 0x13 0x04 0x00 0x14 0x04>;
					clocks = <0x02 0xe4>;
					clock-names = "snvs-rtc";
					status = "disabled";
					phandle = <0x96>;
				};

				snvs-powerkey {
					compatible = "fsl,sec-v4.0-pwrkey";
					regmap = <0x1b>;
					interrupts = <0x00 0x04 0x04>;
					clocks = <0x02 0xe4>;
					clock-names = "snvs-pwrkey";
					linux,keycode = <0x74>;
					wakeup-source;
					status = "okay";
					phandle = <0x97>;
				};

				snvs-lpgpr {
					compatible = "fsl,imx8mm-snvs-lpgpr\0fsl,imx7d-snvs-lpgpr";
					phandle = <0x98>;
				};
			};

			clock-controller@30380000 {
				compatible = "fsl,imx8mm-ccm";
				reg = <0x30380000 0x10000>;
				#clock-cells = <0x01>;
				clocks = <0x1c 0x1d 0x1e 0x1f 0x20 0x21>;
				clock-names = "osc_32k\0osc_24m\0clk_ext1\0clk_ext2\0clk_ext3\0clk_ext4";
				assigned-clocks = <0x02 0x42 0x02 0xfb 0x02 0x5b 0x02 0x5e 0x02 0x60 0x02 0x1b 0x02 0x14 0x02 0x12 0x02 0x13>;
				assigned-clock-parents = <0x02 0x38 0x02 0x2c 0x02 0x2f 0x02 0x38>;
				assigned-clock-rates = <0x00 0x00 0x00 0x17d78400 0x17d78400 0x2cb41780 0x3df582e0 0x17700000 0x15888000>;
				phandle = <0x02>;
			};

			reset-controller@30390000 {
				compatible = "fsl,imx8mm-src\0fsl,imx8mq-src\0syscon";
				reg = <0x30390000 0x10000>;
				interrupts = <0x00 0x59 0x04>;
				#reset-cells = <0x01>;
				phandle = <0x23>;
			};

			gpc@303a0000 {
				compatible = "fsl,imx8mm-gpc";
				reg = <0x303a0000 0x10000>;
				interrupts = <0x00 0x57 0x04>;
				interrupt-parent = <0x01>;
				interrupt-controller;
				#interrupt-cells = <0x03>;
				phandle = <0x99>;

				pgc {
					#address-cells = <0x01>;
					#size-cells = <0x00>;

					power-domain@0 {
						#power-domain-cells = <0x00>;
						reg = <0x00>;
						clocks = <0x02 0x58>;
						assigned-clocks = <0x02 0x58>;
						assigned-clock-parents = <0x02 0x40>;
						phandle = <0x22>;
					};

					power-domain@1 {
						#power-domain-cells = <0x00>;
						reg = <0x01>;
						power-domains = <0x22>;
						clocks = <0x02 0xa9>;
						phandle = <0x6e>;
					};

					power-domain@2 {
						#power-domain-cells = <0x00>;
						reg = <0x02>;
						phandle = <0x0f>;
					};

					power-domain@3 {
						#power-domain-cells = <0x00>;
						reg = <0x03>;
						phandle = <0x10>;
					};

					power-domain@4 {
						#power-domain-cells = <0x00>;
						reg = <0x04>;
						clocks = <0x02 0xc8 0x02 0x5a>;
						assigned-clocks = <0x02 0x59 0x02 0x5a>;
						assigned-clock-parents = <0x02 0x38 0x02 0x38>;
						assigned-clock-rates = <0x2faf0800 0x17d78400>;
						phandle = <0x24>;
					};

					power-domain@5 {
						#power-domain-cells = <0x00>;
						reg = <0x05>;
						clocks = <0x02 0x5a 0x02 0xc8 0x02 0xd9 0x02 0xc1>;
						resets = <0x23 0x20>;
						power-domains = <0x24>;
						phandle = <0x75>;
					};

					power-domain@6 {
						#power-domain-cells = <0x00>;
						reg = <0x06>;
						clocks = <0x02 0xd2>;
						assigned-clocks = <0x02 0x54>;
						assigned-clock-parents = <0x02 0x38>;
						phandle = <0x70>;
					};

					power-domain@7 {
						#power-domain-cells = <0x00>;
						reg = <0x07>;
						phandle = <0x71>;
					};

					power-domain@8 {
						#power-domain-cells = <0x00>;
						reg = <0x08>;
						phandle = <0x72>;
					};

					power-domain@9 {
						#power-domain-cells = <0x00>;
						reg = <0x09>;
						phandle = <0x73>;
					};

					power-domain@10 {
						#power-domain-cells = <0x00>;
						reg = <0x0a>;
						clocks = <0x02 0xce 0x02 0xcd>;
						assigned-clocks = <0x02 0x55 0x02 0x56>;
						assigned-clock-parents = <0x02 0x41 0x02 0x38>;
						assigned-clock-rates = <0x1dcd6500 0xbebc200>;
						phandle = <0x65>;
					};

					power-domain@11 {
						#power-domain-cells = <0x00>;
						reg = <0x0b>;
						phandle = <0x66>;
					};
				};
			};
		};

		bus@30400000 {
			compatible = "fsl,aips-bus\0simple-bus";
			reg = <0x30400000 0x400000>;
			#address-cells = <0x01>;
			#size-cells = <0x01>;
			ranges = <0x30400000 0x30400000 0x400000>;
			phandle = <0x9a>;

			pwm@30660000 {
				compatible = "fsl,imx8mm-pwm\0fsl,imx27-pwm";
				reg = <0x30660000 0x10000>;
				interrupts = <0x00 0x51 0x04>;
				clocks = <0x02 0xaa 0x02 0xaa>;
				clock-names = "ipg\0per";
				#pwm-cells = <0x03>;
				status = "okay";
				pinctrl-names = "default";
				pinctrl-0 = <0x25>;
				phandle = <0x7e>;
			};

			pwm@30670000 {
				compatible = "fsl,imx8mm-pwm\0fsl,imx27-pwm";
				reg = <0x30670000 0x10000>;
				interrupts = <0x00 0x52 0x04>;
				clocks = <0x02 0xab 0x02 0xab>;
				clock-names = "ipg\0per";
				#pwm-cells = <0x03>;
				status = "disabled";
				phandle = <0x9b>;
			};

			pwm@30680000 {
				compatible = "fsl,imx8mm-pwm\0fsl,imx27-pwm";
				reg = <0x30680000 0x10000>;
				interrupts = <0x00 0x53 0x04>;
				clocks = <0x02 0xac 0x02 0xac>;
				clock-names = "ipg\0per";
				#pwm-cells = <0x03>;
				status = "disabled";
				phandle = <0x9c>;
			};

			pwm@30690000 {
				compatible = "fsl,imx8mm-pwm\0fsl,imx27-pwm";
				reg = <0x30690000 0x10000>;
				interrupts = <0x00 0x54 0x04>;
				clocks = <0x02 0xad 0x02 0xad>;
				clock-names = "ipg\0per";
				#pwm-cells = <0x03>;
				status = "disabled";
				phandle = <0x9d>;
			};

			timer@306a0000 {
				compatible = "nxp,sysctr-timer";
				reg = <0x306a0000 0x20000>;
				interrupts = <0x00 0x2f 0x04>;
				clocks = <0x1d>;
				clock-names = "per";
				phandle = <0x9e>;
			};
		};

		bus@30800000 {
			compatible = "fsl,aips-bus\0simple-bus";
			reg = <0x30800000 0x400000>;
			#address-cells = <0x01>;
			#size-cells = <0x01>;
			ranges = <0x30800000 0x30800000 0x400000 0x8000000 0x8000000 0x10000000>;
			phandle = <0x9f>;

			spba-bus@30800000 {
				compatible = "fsl,spba-bus\0simple-bus";
				#address-cells = <0x01>;
				#size-cells = <0x01>;
				reg = <0x30800000 0x100000>;
				ranges;
				phandle = <0xa0>;

				spi@30820000 {
					compatible = "fsl,imx8mm-ecspi\0fsl,imx51-ecspi";
					#address-cells = <0x01>;
					#size-cells = <0x00>;
					reg = <0x30820000 0x10000>;
					interrupts = <0x00 0x1f 0x04>;
					clocks = <0x02 0x9f 0x02 0x9f>;
					clock-names = "ipg\0per";
					dmas = <0x26 0x00 0x07 0x01 0x26 0x01 0x07 0x02>;
					dma-names = "rx\0tx";
					status = "okay";
					pinctrl-names = "default";
					pinctrl-0 = <0x27>;
					cs-gpios = <0x28 0x09 0x01 0x29 0x0c 0x01 0x2a 0x16 0x01>;
					phandle = <0xa1>;

					can@1 {
						compatible = "microchip,mcp251xfd";
						reg = <0x01>;
						pinctrl-names = "default";
						pinctrl-0 = <0x2b>;
						clocks = <0x2c>;
						interrupt-parent = <0x29>;
						interrupts = <0x06 0x02>;
						microchip,rx-int-gpios = <0x28 0x04 0x01>;
						spi-max-frequency = <0x1312d00>;
						status = "disabled";
						phandle = <0xa2>;
					};

					spidev@0 {
						compatible = "var,spidev";
						spi-max-frequency = <0xb71b00>;
						reg = <0x00>;
					};

					spidev@2 {
						reg = <0x02>;
						compatible = "var,spidev";
						spi-max-frequency = <0xb71b00>;
						status = "okay";
					};
				};

				spi@30830000 {
					compatible = "fsl,imx8mm-ecspi\0fsl,imx51-ecspi";
					#address-cells = <0x01>;
					#size-cells = <0x00>;
					reg = <0x30830000 0x10000>;
					interrupts = <0x00 0x20 0x04>;
					clocks = <0x02 0xa0 0x02 0xa0>;
					clock-names = "ipg\0per";
					dmas = <0x26 0x02 0x07 0x01 0x26 0x03 0x07 0x02>;
					dma-names = "rx\0tx";
					status = "disabled";
					phandle = <0xa3>;
				};

				spi@30840000 {
					compatible = "fsl,imx8mm-ecspi\0fsl,imx51-ecspi";
					#address-cells = <0x01>;
					#size-cells = <0x00>;
					reg = <0x30840000 0x10000>;
					interrupts = <0x00 0x21 0x04>;
					clocks = <0x02 0xa1 0x02 0xa1>;
					clock-names = "ipg\0per";
					dmas = <0x26 0x04 0x07 0x01 0x26 0x05 0x07 0x02>;
					dma-names = "rx\0tx";
					status = "disabled";
					phandle = <0xa4>;
				};

				serial@30860000 {
					compatible = "fsl,imx8mm-uart\0fsl,imx6q-uart";
					reg = <0x30860000 0x10000>;
					interrupts = <0x00 0x1a 0x04>;
					clocks = <0x02 0xbc 0x02 0xbc>;
					clock-names = "ipg\0per";
					dmas = <0x26 0x16 0x04 0x00 0x26 0x17 0x04 0x00>;
					dma-names = "rx\0tx";
					status = "okay";
					pinctrl-names = "default";
					pinctrl-0 = <0x2d>;
					wakeup-source;
					phandle = <0xa5>;
				};

				serial@30880000 {
					compatible = "fsl,imx8mm-uart\0fsl,imx6q-uart";
					reg = <0x30880000 0x10000>;
					interrupts = <0x00 0x1c 0x04>;
					clocks = <0x02 0xbe 0x02 0xbe>;
					clock-names = "ipg\0per";
					dmas = <0x26 0x1a 0x04 0x00 0x26 0x1b 0x04 0x00>;
					dma-names = "rx\0tx";
					status = "okay";
					pinctrl-names = "default";
					pinctrl-0 = <0x2e>;
					phandle = <0xa6>;
				};

				serial@30890000 {
					compatible = "fsl,imx8mm-uart\0fsl,imx6q-uart";
					reg = <0x30890000 0x10000>;
					interrupts = <0x00 0x1b 0x04>;
					clocks = <0x02 0xbd 0x02 0xbd>;
					clock-names = "ipg\0per";
					status = "disabled";
					pinctrl-names = "default";
					pinctrl-0 = <0x2f>;
					phandle = <0xa7>;
				};
			};

			crypto@30900000 {
				compatible = "fsl,sec-v4.0";
				#address-cells = <0x01>;
				#size-cells = <0x01>;
				reg = <0x30900000 0x40000>;
				ranges = <0x00 0x30900000 0x40000>;
				interrupts = <0x00 0x5b 0x04>;
				clocks = <0x02 0x5d 0x02 0x5f>;
				clock-names = "aclk\0ipg";
				phandle = <0xa8>;

				jr@1000 {
					compatible = "fsl,sec-v4.0-job-ring";
					reg = <0x1000 0x1000>;
					interrupts = <0x00 0x69 0x04>;
					status = "disabled";
					phandle = <0xa9>;
				};

				jr@2000 {
					compatible = "fsl,sec-v4.0-job-ring";
					reg = <0x2000 0x1000>;
					interrupts = <0x00 0x6a 0x04>;
					phandle = <0xaa>;
				};

				jr@3000 {
					compatible = "fsl,sec-v4.0-job-ring";
					reg = <0x3000 0x1000>;
					interrupts = <0x00 0x72 0x04>;
					phandle = <0xab>;
				};
			};

			i2c@30a20000 {
				compatible = "fsl,imx8mm-i2c\0fsl,imx21-i2c";
				#address-cells = <0x01>;
				#size-cells = <0x00>;
				reg = <0x30a20000 0x10000>;
				interrupts = <0x00 0x23 0x04>;
				clocks = <0x02 0xa4>;
				status = "okay";
				clock-frequency = <0x186a0>;
				pinctrl-names = "default\0gpio";
				pinctrl-0 = <0x30>;
				pinctrl-1 = <0x31>;
				scl-gpios = <0x28 0x0e 0x00>;
				sda-gpios = <0x28 0x0f 0x00>;
				phandle = <0xac>;

				sn65dsi84@2c {
					compatible = "ti,sn65dsi84";
					reg = <0x2c>;
					enable-gpios = <0x32 0x0b 0x00>;
					pinctrl-names = "default";
					pinctrl-0 = <0x33>;
					status = "disabled";
					phandle = <0xad>;

					ports {
						#address-cells = <0x01>;
						#size-cells = <0x00>;

						port@0 {
							reg = <0x00>;

							endpoint {
								remote-endpoint = <0x34>;
								data-lanes = <0x01 0x02 0x03 0x04>;
								phandle = <0x61>;
							};
						};

						port@2 {
							reg = <0x02>;

							endpoint {
								remote-endpoint = <0x35>;
								phandle = <0x77>;
							};
						};
					};
				};

				pmic@4b {
					compatible = "rohm,bd71847";
					reg = <0x4b>;
					pinctrl-names = "default";
					pinctrl-0 = <0x36>;
					interrupt-parent = <0x32>;
					interrupts = <0x08 0x08>;
					rohm,reset-snvs-powered;
					status = "okay";

					regulators {

						BUCK1 {
							regulator-name = "BUCK1";
							regulator-min-microvolt = <0xaae60>;
							regulator-max-microvolt = <0x13d620>;
							regulator-boot-on;
							regulator-always-on;
							regulator-ramp-delay = <0x4e2>;
							phandle = <0xae>;
						};

						BUCK2 {
							regulator-name = "BUCK2";
							regulator-min-microvolt = <0xaae60>;
							regulator-max-microvolt = <0x13d620>;
							regulator-boot-on;
							regulator-always-on;
							regulator-ramp-delay = <0x4e2>;
							rohm,dvs-run-voltage = <0xf4240>;
							rohm,dvs-idle-voltage = <0xdbba0>;
							phandle = <0x07>;
						};

						BUCK3 {
							regulator-name = "BUCK3";
							regulator-min-microvolt = <0xaae60>;
							regulator-max-microvolt = <0x149970>;
							regulator-boot-on;
							regulator-always-on;
							phandle = <0xaf>;
						};

						BUCK4 {
							regulator-name = "BUCK4";
							regulator-min-microvolt = <0x27ac40>;
							regulator-max-microvolt = <0x325aa0>;
							regulator-boot-on;
							regulator-always-on;
							phandle = <0xb0>;
						};

						BUCK5 {
							regulator-name = "BUCK5";
							regulator-min-microvolt = <0x187d88>;
							regulator-max-microvolt = <0x1e70f8>;
							regulator-boot-on;
							regulator-always-on;
							phandle = <0xb1>;
						};

						BUCK6 {
							regulator-name = "BUCK6";
							regulator-min-microvolt = "\0\f5";
							regulator-max-microvolt = <0x155cc0>;
							regulator-boot-on;
							regulator-always-on;
							phandle = <0xb2>;
						};

						LDO1 {
							regulator-name = "LDO1";
							regulator-min-microvolt = <0x186a00>;
							regulator-max-microvolt = <0x1cfde0>;
							regulator-boot-on;
							regulator-always-on;
							phandle = <0xb3>;
						};

						LDO2 {
							regulator-name = "LDO2";
							regulator-min-microvolt = "\0\f5";
							regulator-max-microvolt = <0xdbba0>;
							regulator-boot-on;
							regulator-always-on;
							phandle = <0xb4>;
						};

						LDO3 {
							regulator-name = "LDO3";
							regulator-min-microvolt = <0x1b7740>;
							regulator-max-microvolt = <0x325aa0>;
							regulator-boot-on;
							regulator-always-on;
							phandle = <0xb5>;
						};

						LDO4 {
							regulator-name = "LDO4";
							regulator-min-microvolt = <0xdbba0>;
							regulator-max-microvolt = <0x1b7740>;
							regulator-always-on;
							phandle = <0xb6>;
						};

						LDO5 {
							regulator-name = "LDO5";
							regulator-min-microvolt = <0x1b7740>;
							regulator-max-microvolt = <0x1b7740>;
							regulator-always-on;
							phandle = <0x43>;
						};

						LDO6 {
							regulator-name = "LDO6";
							regulator-min-microvolt = <0xdbba0>;
							regulator-max-microvolt = <0x1b7740>;
							regulator-boot-on;
							regulator-always-on;
							phandle = <0xb7>;
						};
					};
				};

				tpm@2e {
					compatible = "infineon,slb9673\0tcg,tpm-tis-i2c";
					reg = <0x2e>;
					label = "tpm";
				};
			};

			i2c@30a30000 {
				compatible = "fsl,imx8mm-i2c\0fsl,imx21-i2c";
				#address-cells = <0x01>;
				#size-cells = <0x00>;
				reg = <0x30a30000 0x10000>;
				interrupts = <0x00 0x24 0x04>;
				clocks = <0x02 0xa5>;
				status = "okay";
				clock-frequency = <0x186a0>;
				pinctrl-names = "default\0gpio";
				pinctrl-0 = <0x37>;
				pinctrl-1 = <0x38>;
				scl-gpios = <0x28 0x10 0x00>;
				sda-gpios = <0x28 0x11 0x00>;
				phandle = <0xb8>;

				typec@3d {
					compatible = "nxp,ptn5150";
					pinctrl-names = "default";
					pinctrl-0 = <0x39>;
					reg = <0x3d>;
					interrupt-parent = <0x29>;
					interrupts = <0x0a 0x00>;
					irq-is-id-quirk;
					status = "disabled";
					phandle = <0xb9>;
				};

				ft5x06_ts@38 {
					compatible = "edt,edt-ft5206";
					reg = <0x38>;
					pinctrl-names = "default";
					pinctrl-0 = <0x3b>;
					reset-gpios = <0x3c 0x04 0x01>;
					interrupt-parent = <0x29>;
					interrupts = <0x0e 0x02>;
					touchscreen-size-x = <0x320>;
					touchscreen-size-y = <0x1e0>;
					touchscreen-inverted-x;
					touchscreen-inverted-y;
					wakeup-source;
					status = "disabled";
					phandle = <0xba>;
				};

				ov5640_mipi1@3c {
					compatible = "ovti,ov5640_mipi";
					reg = <0x3c>;
					clocks = <0x02 0x9e>;
					clock-names = "csi_mclk";
					csi_id = <0x00>;
					pwn-gpios = <0x3d 0x03 0x00>;
					rst-gpios = <0x3d 0x01 0x01>;
					mclk = <0x16e3600>;
					mclk_source = <0x00>;
					status = "disabled";
					phandle = <0xbb>;

					port {

						endpoint {
							remote-endpoint = <0x3e>;
							phandle = <0x63>;
						};
					};
				};
			};

			i2c@30a40000 {
				#address-cells = <0x01>;
				#size-cells = <0x00>;
				compatible = "fsl,imx8mm-i2c\0fsl,imx21-i2c";
				reg = <0x30a40000 0x10000>;
				interrupts = <0x00 0x25 0x04>;
				clocks = <0x02 0xa6>;
				status = "okay";
				clock-frequency = <0x186a0>;
				pinctrl-names = "default\0gpio";
				pinctrl-0 = <0x40>;
				pinctrl-1 = <0x41>;
				scl-gpios = <0x28 0x12 0x00>;
				sda-gpios = <0x28 0x13 0x00>;
				phandle = <0xbc>;

				audio-codec@1a {
					compatible = "wlf,wm8904";
					#sound-dai-cells = <0x00>;
					reg = <0x1a>;
					clocks = <0x02 0xb4>;
					clock-names = "mclk";
					DBVDD-supply = <0x42>;
					DCVDD-supply = <0x43>;
					AVDD-supply = <0x43>;
					CPVDD-supply = <0x43>;
					MICVDD-supply = <0x43>;
					num-drc-cfgs = <0x05>;
					drc-cfg-names = "default\0peaklimiter\0tradition\0soft\0music";
					drc-cfg-regs = <0x1af 0x3248 0x00 0x00 0x4af 0x324b 0x10 0x408 0x4af 0x324b 0x28 0x704 0x4af 0x324b 0x18 0x78c 0x4af 0x324b 0x10 0x50e>;
					gpio-cfg = <0x18 0xffff 0xffff 0xffff>;
					status = "okay";
					phandle = <0x7a>;
				};

				rtc@68 {
					compatible = "dallas,ds1337";
					reg = <0x68>;
					pinctrl-names = "default";
					pinctrl-0 = <0x3f>;
					interrupt-parent = <0x29>;
					interrupts = <0x03 0x02>;
					wakeup-source;
					status = "okay";
				};
			};

			i2c@30a50000 {
				compatible = "fsl,imx8mm-i2c\0fsl,imx21-i2c";
				#address-cells = <0x01>;
				#size-cells = <0x00>;
				reg = <0x30a50000 0x10000>;
				interrupts = <0x00 0x26 0x04>;
				clocks = <0x02 0xa7>;
				status = "okay";
				clock-frequency = <0x186a0>;
				pinctrl-names = "default\0gpio";
				pinctrl-0 = <0x44>;
				pinctrl-1 = <0x45>;
				scl-gpios = <0x28 0x14 0x00>;
				sda-gpios = <0x28 0x15 0x00>;
				phandle = <0xbd>;

				gpio@20 {
					compatible = "nxp,pcal6408";
					standard-regs-fallback;
					reg = <0x20>;
					gpio-controller;
					#gpio-cells = <0x02>;
					pinctrl-names = "default";
					pinctrl-0 = <0x46>;
					interrupt-parent = <0x29>;
					interrupts = <0x05 0x02>;
					phandle = <0x3d>;
				};

				gpio@21 {
					compatible = "nxp,pcal6408";
					standard-regs-fallback;
					reg = <0x21>;
					gpio-controller;
					#gpio-cells = <0x02>;
					phandle = <0x3c>;
				};
			};

			serial@30a60000 {
				compatible = "fsl,imx8mm-uart\0fsl,imx6q-uart";
				reg = <0x30a60000 0x10000>;
				interrupts = <0x00 0x1d 0x04>;
				clocks = <0x02 0xbf 0x02 0xbf>;
				clock-names = "ipg\0per";
				dmas = <0x26 0x1c 0x04 0x00 0x26 0x1d 0x04 0x00>;
				dma-names = "rx\0tx";
				status = "okay";
				pinctrl-names = "default";
				pinctrl-0 = <0x47 0x48>;
				assigned-clocks = <0x02 0x82>;
				assigned-clock-parents = <0x02 0x31>;
				uart-has-rtscts;
				phandle = <0xbe>;

				bluetooth_iw61x {
					compatible = "nxp,88w8987-bt";
					status = "okay";
					phandle = <0xbf>;
				};
			};

			mailbox@30aa0000 {
				compatible = "fsl,imx8mm-mu\0fsl,imx6sx-mu";
				reg = <0x30aa0000 0x10000>;
				interrupts = <0x00 0x58 0x04>;
				clocks = <0x02 0xda>;
				#mbox-cells = <0x02>;
				status = "okay";
				phandle = <0xc0>;
			};

			mmc@30b40000 {
				compatible = "fsl,imx8mm-usdhc\0fsl,imx7d-usdhc";
				reg = <0x30b40000 0x10000>;
				interrupts = <0x00 0x16 0x04>;
				clocks = <0x02 0x5f 0x02 0x53 0x02 0xc2>;
				clock-names = "ipg\0ahb\0per";
				fsl,tuning-start-tap = <0x14>;
				fsl,tuning-step = <0x02>;
				bus-width = <0x04>;
				status = "okay";
				#address-cells = <0x01>;
				#size-cells = <0x00>;
				pinctrl-names = "default\0state_100mhz\0state_200mhz";
				pinctrl-0 = <0x49 0x4a>;
				pinctrl-1 = <0x4b 0x4a>;
				pinctrl-2 = <0x4c 0x4a>;
				non-removable;
				keep-power-in-suspend;
				mmc-pwrseq = <0x4d>;
				phandle = <0xc1>;
			};

			mmc@30b50000 {
				compatible = "fsl,imx8mm-usdhc\0fsl,imx7d-usdhc";
				reg = <0x30b50000 0x10000>;
				interrupts = <0x00 0x17 0x04>;
				clocks = <0x02 0x5f 0x02 0x53 0x02 0xc3>;
				clock-names = "ipg\0ahb\0per";
				fsl,tuning-start-tap = <0x14>;
				fsl,tuning-step = <0x02>;
				bus-width = <0x04>;
				status = "okay";
				pinctrl-names = "default\0state_100mhz\0state_200mhz";
				pinctrl-0 = <0x4e 0x4f>;
				pinctrl-1 = <0x50 0x4f>;
				pinctrl-2 = <0x51 0x4f>;
				cd-gpios = <0x32 0x0c 0x01>;
				vmmc-supply = <0x52>;
				phandle = <0xc2>;
			};

			mmc@30b60000 {
				compatible = "fsl,imx8mm-usdhc\0fsl,imx7d-usdhc";
				reg = <0x30b60000 0x10000>;
				interrupts = <0x00 0x18 0x04>;
				clocks = <0x02 0x5f 0x02 0x53 0x02 0xd0>;
				clock-names = "ipg\0ahb\0per";
				fsl,tuning-start-tap = <0x14>;
				fsl,tuning-step = <0x02>;
				bus-width = <0x08>;
				status = "okay";
				pinctrl-names = "default\0state_100mhz\0state_200mhz";
				pinctrl-0 = <0x53>;
				pinctrl-1 = <0x54>;
				pinctrl-2 = <0x55>;
				non-removable;
				phandle = <0xc3>;
			};

			spi@30bb0000 {
				#address-cells = <0x01>;
				#size-cells = <0x00>;
				compatible = "nxp,imx8mm-fspi";
				reg = <0x30bb0000 0x10000 0x8000000 0x10000000>;
				reg-names = "fspi_base\0fspi_mmap";
				interrupts = <0x00 0x6b 0x04>;
				clocks = <0x02 0xae 0x02 0xae>;
				clock-names = "fspi_en\0fspi";
				status = "disabled";
				pinctrl-names = "default";
				pinctrl-0 = <0x56>;
				phandle = <0xc4>;
			};

			dma-controller@30bd0000 {
				compatible = "fsl,imx8mm-sdma\0fsl,imx8mq-sdma";
				reg = <0x30bd0000 0x10000>;
				interrupts = <0x00 0x02 0x04>;
				clocks = <0x02 0xd3 0x02 0x5d>;
				clock-names = "ipg\0ahb";
				#dma-cells = <0x03>;
				fsl,sdma-ram-script-name = "imx/sdma/sdma-imx7d.bin";
				phandle = <0x26>;
			};

			ethernet@30be0000 {
				compatible = "fsl,imx8mm-fec\0fsl,imx8mq-fec\0fsl,imx6sx-fec";
				reg = <0x30be0000 0x10000>;
				interrupts = <0x00 0x76 0x04 0x00 0x77 0x04 0x00 0x78 0x04 0x00 0x79 0x04>;
				clocks = <0x02 0xa2 0x02 0xa2 0x02 0x75 0x02 0x74 0x02 0x76>;
				clock-names = "ipg\0ahb\0ptp\0enet_clk_ref\0enet_out";
				assigned-clocks = <0x02 0x52 0x02 0x75 0x02 0x74 0x02 0x76>;
				assigned-clock-parents = <0x02 0x36 0x02 0x3a 0x02 0x3b 0x02 0x39>;
				assigned-clock-rates = <0x00 0x5f5e100 0x7735940 0x00>;
				fsl,num-tx-queues = <0x03>;
				fsl,num-rx-queues = <0x03>;
				nvmem-cells = <0x57>;
				nvmem-cell-names = "mac-address";
				fsl,stop-mode = <0x58 0x10 0x03>;
				status = "okay";
				pinctrl-names = "default\0sleep";
				pinctrl-0 = <0x59>;
				pinctrl-1 = <0x5a>;
				phy-mode = "rgmii";
				phy-handle = <0x5b>;
				phy-supply = <0x5c>;
				phandle = <0xc5>;

				mdio {
					#address-cells = <0x01>;
					#size-cells = <0x00>;

					ethernet-phy@0 {
						compatible = "ethernet-phy-ieee802.3-c22";
						reg = <0x00>;
						qca,disable-smarteee;
						vddio-supply = <0x5d>;
						reset-gpios = <0x29 0x09 0x01>;
						reset-assert-us = <0x2710>;
						reset-deassert-us = <0x30d40>;
						mxl-8611x,led0_cfg = <0x2600>;
						mxl-8611x,led1_cfg = <0x70>;
						ti,min-output-impedance;
						phandle = <0x5b>;

						vddio-regulator {
							regulator-min-microvolt = <0x1b7740>;
							regulator-max-microvolt = <0x1b7740>;
							phandle = <0x5d>;
						};
					};
				};
			};
		};

		bus@32c00000 {
			compatible = "fsl,aips-bus\0simple-bus";
			reg = <0x32c00000 0x400000>;
			#address-cells = <0x01>;
			#size-cells = <0x01>;
			ranges = <0x32c00000 0x32c00000 0x400000>;
			phandle = <0xc6>;

			lcdif@32e00000 {
				compatible = "fsl,imx8mm-lcdif";
				reg = <0x32e00000 0x10000>;
				clocks = <0x02 0x6b 0x02 0xcd 0x02 0xce>;
				clock-names = "pix\0disp-axi\0disp-apb";
				assigned-clocks = <0x02 0x6b 0x02 0x55 0x02 0x56>;
				assigned-clock-parents = <0x02 0x28 0x02 0x41 0x02 0x38>;
				assigned-clock-rate = <0x2367b880 0x1dcd6500 0xbebc200>;
				interrupts = <0x00 0x05 0x04>;
				power-domains = <0x5e 0x01>;
				status = "disabled";
				phandle = <0xc7>;

				port {
					phandle = <0x11>;

					endpoint {
						remote-endpoint = <0x5f>;
						phandle = <0x60>;
					};
				};
			};

			mipi_dsi@32e10000 {
				#address-cells = <0x01>;
				#size-cells = <0x00>;
				compatible = "fsl,imx8mm-mipi-dsim";
				reg = <0x32e10000 0x400>;
				clocks = <0x02 0x8e 0x02 0x8f 0x02 0xce>;
				clock-names = "cfg\0pll-ref\0apb-root";
				assigned-clocks = <0x02 0x8e 0x02 0x8f>;
				assigned-clock-parents = <0x02 0x36 0x02 0x02>;
				assigned-clock-rates = <0xfdad680 0xb71b00>;
				interrupts = <0x00 0x12 0x04>;
				power-domains = <0x5e 0x02>;
				status = "disabled";
				phandle = <0xc8>;

				port@0 {

					endpoint {
						remote-endpoint = <0x60>;
						phandle = <0x5f>;
					};
				};

				port@1 {

					endpoint {
						remote-endpoint = <0x61>;
						attach-bridge;
						phandle = <0x34>;
					};
				};
			};

			csi1_bridge@32e20000 {
				compatible = "fsl,imx8mm-csi\0fsl,imx8mq-csi\0fsl,imx6s-csi";
				reg = <0x32e20000 0x1000>;
				interrupts = <0x00 0x10 0x04>;
				clocks = <0x02 0xcd 0x02 0xdb 0x02 0xce>;
				clock-names = "disp-axi\0csi_mclk\0disp_dcic";
				power-domains = <0x5e 0x00>;
				status = "okay";
				fsl,mipi-mode;
				phandle = <0xc9>;

				port {

					endpoint {
						remote-endpoint = <0x62>;
						phandle = <0x64>;
					};
				};
			};

			mipi_csi@32e30000 {
				compatible = "fsl,imx8mm-mipi-csi";
				reg = <0x32e30000 0x1000>;
				interrupts = <0x00 0x11 0x04>;
				clock-frequency = <0x13d92d40>;
				clocks = <0x02 0x92 0x02 0xcd 0x02 0xce>;
				clock-names = "mipi_clk\0disp_axi\0disp_apb";
				bus-width = <0x04>;
				power-domains = <0x5e 0x03>;
				status = "okay";
				phandle = <0xca>;

				port {
					#address-cells = <0x01>;
					#size-cells = <0x00>;

					endpoint@1 {
						reg = <0x01>;
						remote-endpoint = <0x63>;
						data-lanes = <0x02>;
						csis-hs-settle = <0x0d>;
						csis-clk-settle = <0x02>;
						csis-wclk;
						phandle = <0x3e>;
					};

					endpoint@2 {
						reg = <0x02>;
						remote-endpoint = <0x64>;
						phandle = <0x62>;
					};
				};
			};

			blk-ctrl@32e28000 {
				compatible = "fsl,imx8mm-disp-blk-ctrl\0syscon";
				reg = <0x32e28000 0x100>;
				power-domains = <0x65 0x65 0x65 0x66 0x66>;
				power-domain-names = "bus\0csi-bridge\0lcdif\0mipi-dsi\0mipi-csi";
				clocks = <0x02 0xcd 0x02 0xce 0x02 0xdb 0x02 0xcd 0x02 0xce 0x02 0xcc 0x02 0x8e 0x02 0x8f 0x02 0x92 0x02 0xce>;
				clock-names = "csi-bridge-axi\0csi-bridge-apb\0csi-bridge-core\0lcdif-axi\0lcdif-apb\0lcdif-pix\0dsi-pclk\0dsi-ref\0csi-aclk\0csi-pclk";
				#power-domain-cells = <0x01>;
				phandle = <0x5e>;
			};

			usb@32e40000 {
				compatible = "fsl,imx8mm-usb\0fsl,imx7d-usb\0fsl,imx27-usb";
				reg = <0x32e40000 0x200>;
				interrupts = <0x00 0x28 0x04>;
				clocks = <0x02 0xc0>;
				clock-names = "usb1_ctrl_root_clk";
				assigned-clocks = <0x02 0x58>;
				assigned-clock-parents = <0x02 0x40>;
				phys = <0x67>;
				fsl,usbmisc = <0x68 0x00>;
				power-domains = <0x22>;
				status = "okay";
				dr_mode = "host";
				hnp-disable;
				srp-disable;
				adp-disable;
				disable-over-current;
				samsung,picophy-pre-emp-curr-control = <0x03>;
				samsung,picophy-dc-vol-level-adjust = <0x07>;
				phandle = <0xcb>;
			};

			usbmisc@32e40200 {
				compatible = "fsl,imx8mm-usbmisc\0fsl,imx7d-usbmisc\0fsl,imx6q-usbmisc";
				#index-cells = <0x01>;
				reg = <0x32e40200 0x200>;
				phandle = <0x68>;
			};

			usb@32e50000 {
				compatible = "fsl,imx8mm-usb\0fsl,imx7d-usb\0fsl,imx27-usb";
				reg = <0x32e50000 0x200>;
				interrupts = <0x00 0x29 0x04>;
				clocks = <0x02 0xc0>;
				clock-names = "usb1_ctrl_root_clk";
				assigned-clocks = <0x02 0x58>;
				assigned-clock-parents = <0x02 0x40>;
				phys = <0x6a>;
				fsl,usbmisc = <0x6b 0x00>;
				power-domains = <0x22>;
				status = "okay";
				dr_mode = "host";
				samsung,picophy-pre-emp-curr-control = <0x03>;
				samsung,picophy-dc-vol-level-adjust = <0x07>;
				disable-over-current;
				phandle = <0xcc>;
			};

			usbmisc@32e50200 {
				compatible = "fsl,imx8mm-usbmisc\0fsl,imx7d-usbmisc\0fsl,imx6q-usbmisc";
				#index-cells = <0x01>;
				reg = <0x32e50200 0x200>;
				phandle = <0x6b>;
			};

			pcie-phy@32f00000 {
				compatible = "fsl,imx8mm-pcie-phy";
				reg = <0x32f00000 0x10000>;
				clocks = <0x6c>;
				clock-names = "ref";
				assigned-clocks = <0x02 0x68>;
				assigned-clock-rates = <0x5f5e100>;
				assigned-clock-parents = <0x02 0x3a>;
				resets = <0x23 0x1a>;
				reset-names = "pciephy";
				#phy-cells = <0x00>;
				status = "okay";
				fsl,refclk-pad-mode = <0x01>;
				fsl,tx-deemph-gen1 = <0x2d>;
				fsl,tx-deemph-gen2 = <0x0f>;
				fsl,clkreq-unsupported;
				phandle = <0x6f>;
			};
		};

		dma-controller@33000000 {
			compatible = "fsl,imx7d-dma-apbh\0fsl,imx28-dma-apbh";
			reg = <0x33000000 0x2000>;
			interrupts = <0x00 0x0c 0x04 0x00 0x0c 0x04 0x00 0x0c 0x04 0x00 0x0c 0x04>;
			#dma-cells = <0x01>;
			dma-channels = <0x04>;
			clocks = <0x02 0xde>;
			phandle = <0x6d>;
		};

		nand-controller@33002000 {
			compatible = "fsl,imx8mm-gpmi-nand\0fsl,imx7d-gpmi-nand";
			#address-cells = <0x01>;
			#size-cells = <0x00>;
			reg = <0x33002000 0x2000 0x33004000 0x4000>;
			reg-names = "gpmi-nand\0bch";
			interrupts = <0x00 0x0e 0x04>;
			interrupt-names = "bch";
			clocks = <0x02 0xaf 0x02 0xde>;
			clock-names = "gpmi_io\0gpmi_bch_apb";
			dmas = <0x6d 0x00>;
			dma-names = "rx-tx";
			status = "disabled";
			phandle = <0xcd>;
		};

		pcie@33800000 {
			compatible = "fsl,imx8mm-pcie";
			reg = <0x33800000 0x400000 0x1ff00000 0x80000>;
			reg-names = "dbi\0config";
			#address-cells = <0x03>;
			#size-cells = <0x02>;
			device_type = "pci";
			bus-range = <0x00 0xff>;
			ranges = <0x81000000 0x00 0x00 0x1ff80000 0x00 0x10000 0x82000000 0x00 0x18000000 0x18000000 0x00 0x7f00000>;
			num-lanes = <0x01>;
			num-viewport = <0x04>;
			interrupts = <0x00 0x7a 0x04>;
			interrupt-names = "msi";
			#interrupt-cells = <0x01>;
			interrupt-map-mask = <0x00 0x00 0x00 0x07>;
			interrupt-map = <0x00 0x00 0x00 0x01 0x01 0x00 0x7d 0x04 0x00 0x00 0x00 0x02 0x01 0x00 0x7c 0x04 0x00 0x00 0x00 0x03 0x01 0x00 0x7b 0x04 0x00 0x00 0x00 0x04 0x01 0x00 0x7a 0x04>;
			fsl,max-link-speed = <0x02>;
			linux,pci-domain = <0x00>;
			clocks = <0x02 0xa9 0x6c 0x02 0x69>;
			clock-names = "pcie\0pcie_bus\0pcie_aux";
			power-domains = <0x6e>;
			resets = <0x23 0x1c 0x23 0x1d>;
			reset-names = "apps\0turnoff";
			phys = <0x6f>;
			phy-names = "pcie-phy";
			status = "disabled";
			reset-gpio = <0x3c 0x03 0x01>;
			assigned-clocks = <0x02 0x69 0x02 0x67>;
			assigned-clock-rates = <0x989680 0xee6b280>;
			assigned-clock-parents = <0x02 0x39 0x02 0x3e>;
			phandle = <0xce>;
		};

		pcie-ep@33800000 {
			compatible = "fsl,imx8mm-pcie-ep";
			reg = <0x33800000 0x100000 0x33900000 0x100000 0x33b00000 0x100000 0x18000000 0x8000000>;
			reg-names = "dbi\0dbi2\0atu\0addr_space";
			num-lanes = <0x01>;
			interrupts = <0x00 0x7f 0x04>;
			interrupt-names = "dma";
			fsl,max-link-speed = <0x02>;
			clocks = <0x02 0xa9 0x02 0x68 0x02 0x69>;
			clock-names = "pcie\0pcie_bus\0pcie_aux";
			power-domains = <0x6e>;
			resets = <0x23 0x1c 0x23 0x1d>;
			reset-names = "apps\0turnoff";
			phys = <0x6f>;
			phy-names = "pcie-phy";
			num-ib-windows = <0x04>;
			num-ob-windows = <0x04>;
			status = "disabled";
			phandle = <0xcf>;
		};

		blk-ctrl@38330000 {
			compatible = "fsl,imx8mm-vpu-blk-ctrl\0syscon";
			reg = <0x38330000 0x100>;
			power-domains = <0x70 0x71 0x72 0x73>;
			power-domain-names = "bus\0g1\0g2\0h1";
			clocks = <0x02 0xc7 0x02 0xca 0x02 0xc9>;
			clock-names = "g1\0g2\0h1";
			assigned-clocks = <0x02 0x63 0x02 0x64>;
			assigned-clock-parents = <0x02 0x2b 0x02 0x2b>;
			assigned-clock-rates = <0x23c34600 0x23c34600>;
			#power-domain-cells = <0x01>;
			phandle = <0x74>;
		};

		interrupt-controller@38800000 {
			compatible = "arm,gic-v3";
			reg = <0x38800000 0x10000 0x38880000 0xc0000>;
			#interrupt-cells = <0x03>;
			interrupt-controller;
			interrupts = <0x01 0x09 0x04>;
			phandle = <0x01>;
		};

		ddr-pmu@3d800000 {
			compatible = "fsl,imx8mm-ddr-pmu\0fsl,imx8m-ddr-pmu";
			reg = <0x3d800000 0x400000>;
			interrupts = <0x00 0x62 0x04>;
		};
	};

	vpu_h1@38320000 {
		compatible = "nxp,imx8mm-hantro-h1";
		reg = <0x00 0x38320000 0x00 0x10000>;
		reg-names = "regs_hantro_h1";
		interrupts = <0x00 0x1e 0x04>;
		interrupt-names = "irq_hantro_h1";
		clocks = <0x02 0xc9 0x02 0xd2>;
		clock-names = "clk_hantro_h1\0clk_hantro_h1_bus";
		assigned-clocks = <0x02 0x9d 0x02 0x54>;
		assigned-clock-parents = <0x02 0x2b 0x02 0x38>;
		assigned-clock-rates = <0x23c34600 0x2faf0800>;
		power-domains = <0x74 0x02>;
		status = "okay";
		phandle = <0xd0>;
	};

	vpu_g1@38300000 {
		compatible = "nxp,imx8mm-hantro";
		reg = <0x00 0x38300000 0x00 0x100000>;
		reg-names = "regs_hantro";
		interrupts = <0x00 0x07 0x04>;
		interrupt-names = "irq_hantro";
		clocks = <0x02 0xc7 0x02 0xd2>;
		clock-names = "clk_hantro\0clk_hantro_bus";
		assigned-clocks = <0x02 0x63 0x02 0x54>;
		assigned-clock-parents = <0x02 0x2b 0x02 0x38>;
		assigned-clock-rates = <0x23c34600 0x2faf0800>;
		power-domains = <0x74 0x00>;
		status = "okay";
		phandle = <0xd1>;
	};

	vpu_g2@38310000 {
		compatible = "nxp,imx8mm-hantro";
		reg = <0x00 0x38310000 0x00 0x100000>;
		reg-names = "regs_hantro";
		interrupts = <0x00 0x08 0x04>;
		interrupt-names = "irq_hantro";
		clocks = <0x02 0xca 0x02 0xd2>;
		clock-names = "clk_hantro\0clk_hantro_bus";
		assigned-clocks = <0x02 0x64 0x02 0x54>;
		assigned-clock-parents = <0x02 0x2b 0x02 0x38>;
		assigned-clock-rates = <0x23c34600 0x2faf0800>;
		power-domains = <0x74 0x01>;
		status = "okay";
		phandle = <0xd2>;
	};

	vpu_v4l2 {
		compatible = "nxp,imx8m-vsiv4l2";
		status = "okay";
		phandle = <0xd3>;
	};

	gpu@38000000 {
		compatible = "fsl,imx8mm-gpu\0fsl,imx6q-gpu";
		reg = <0x00 0x38000000 0x00 0x8000 0x00 0x38008000 0x00 0x8000 0x00 0x40000000 0x00 0xc0000000 0x00 0x00 0x00 0x8000000>;
		reg-names = "iobase_3d\0iobase_2d\0phys_baseaddr\0contiguous_mem";
		interrupts = <0x00 0x03 0x04 0x00 0x19 0x04>;
		interrupt-names = "irq_3d\0irq_2d";
		clocks = <0x02 0xc1 0x02 0x00 0x02 0xc8 0x02 0x5a 0x02 0xd9 0x02 0xc8 0x02 0x5a>;
		clock-names = "gpu3d_clk\0gpu3d_shader_clk\0gpu3d_axi_clk\0gpu3d_ahb_clk\0gpu2d_clk\0gpu2d_axi_clk\0gpu2d_ahb_clk";
		assigned-clocks = <0x02 0x45 0x02 0x46 0x02 0x59 0x02 0x5a 0x02 0x2a>;
		assigned-clock-parents = <0x02 0x2a 0x02 0x2a 0x02 0x38 0x02 0x38>;
		assigned-clock-rates = <0x00 0x00 0x00 0x17d78400 0x3b9aca00>;
		power-domains = <0x75>;
		status = "okay";
		throttle,max_state = <0x01>;
		#cooling-cells = <0x02>;
		phandle = <0x0e>;
	};

	iw612_pwrseq {
		compatible = "mmc-pwrseq-simple";
		post-power-on-delay-ms = <0x64>;
		power-off-delay-us = <0x2710>;
		reset-gpios = <0x32 0x0a 0x01 0x32 0x14 0x01>;
		status = "okay";
		phandle = <0x4d>;
	};

	memory@40000000 {
		device_type = "memory";
		reg = <0x00 0x40000000 0x00 0x80000000>;
	};

	panel-lvds {
		compatible = "panel-lvds";
		data-mapping = "jeida-24";
		width-mm = <0x9a>;
		height-mm = <0x57>;
		backlight = <0x76>;
		phandle = <0xd4>;

		port {

			endpoint {
				remote-endpoint = <0x77>;
				phandle = <0x35>;
			};
		};

		panel-timing {
			clock-frequency = <0x1f78a40>;
			hactive = <0x320>;
			vactive = <0x1e0>;
			hback-porch = <0x1e>;
			hfront-porch = <0x1e>;
			vback-porch = <0x1d>;
			vfront-porch = <0x0d>;
			hsync-len = <0x30>;
			vsync-len = <0x03>;
			hsync-active = <0x00>;
			vsync-active = <0x00>;
			de-active = <0x01>;
			pixelclk-active = <0x00>;
		};
	};

	audio_vdd {
		compatible = "regulator-fixed";
		regulator-name = "wm8904_supply";
		regulator-min-microvolt = <0x325aa0>;
		regulator-max-microvolt = <0x325aa0>;
		regulator-always-on;
		phandle = <0x42>;
	};

	regulator-eth-phy {
		compatible = "regulator-fixed";
		pinctrl-names = "default";
		pinctrl-0 = <0x78>;
		regulator-name = "eth_phy_pwr";
		regulator-min-microvolt = <0x325aa0>;
		regulator-max-microvolt = <0x325aa0>;
		regulator-enable-ramp-delay = <0x4e20>;
		gpio = <0x29 0x07 0x01>;
		regulator-boot-on;
		phandle = <0x5c>;
	};

	sound-wm8904 {
		compatible = "simple-audio-card";
		simple-audio-card,bitclock-master = <0x79>;
		simple-audio-card,format = "i2s";
		simple-audio-card,frame-master = <0x79>;
		simple-audio-card,name = "wm8904-audio";
		simple-audio-card,routing = "Headphone Jack\0HPOUTL\0Headphone Jack\0HPOUTR\0IN2L\0Line In Jack\0IN2R\0Line In Jack\0IN1L\0Microphone Jack\0IN1R\0Microphone Jack";
		simple-audio-card,widgets = "Microphone\0Microphone Jack\0Headphone\0Headphone Jack\0Line\0Line In Jack";
		simple-audio-card,mclk-fs = <0x100>;

		simple-audio-card,codec {
			sound-dai = <0x7a>;
			phandle = <0x79>;
		};

		simple-audio-card,cpu {
			sound-dai = <0x7b>;
		};
	};

	sound-spdif {
		compatible = "fsl,imx-audio-spdif";
		model = "imx-spdif";
		spdif-controller = <0x7c>;
		spdif-out;
		spdif-in;
		status = "disabled";
	};

	sound-micfil {
		compatible = "fsl,imx-audio-card";
		model = "imx-audio-micfil";

		pri-dai-link {
			link-name = "micfil hifi";
			format = "i2s";

			cpu {
				sound-dai = <0x7d>;
			};
		};
	};

	chosen {
		stdout-path = "/soc@0/bus@30800000/spba-bus@30800000/serial@30860000";
	};

	backlight {
		compatible = "pwm-backlight";
		pwms = <0x7e 0x00 0xf4240 0x00>;
		brightness-levels = <0x00 0x01 0x02 0x03 0x04 0x05 0x06 0x07 0x08 0x09 0x0a 0x0b 0x0c 0x0d 0x0e 0x0f 0x10 0x11 0x12 0x13 0x14 0x15 0x16 0x17 0x18 0x19 0x1a 0x1b 0x1c 0x1d 0x1e 0x1f 0x20 0x21 0x22 0x23 0x24 0x25 0x26 0x27 0x28 0x29 0x2a 0x2b 0x2c 0x2d 0x2e 0x2f 0x30 0x31 0x32 0x33 0x34 0x35 0x36 0x37 0x38 0x39 0x3a 0x3b 0x3c 0x3d 0x3e 0x3f 0x40 0x41 0x42 0x43 0x44 0x45 0x46 0x47 0x48 0x49 0x4a 0x4b 0x4c 0x4d 0x4e 0x4f 0x50 0x51 0x52 0x53 0x54 0x55 0x56 0x57 0x58 0x59 0x5a 0x5b 0x5c 0x5d 0x5e 0x5f 0x60 0x61 0x62 0x63 0x64>;
		default-brightness-level = <0x50>;
		status = "okay";
		phandle = <0x76>;
	};

	gpio-keys {
		compatible = "gpio-keys";
		status = "okay";

		up {
			label = "Up";
			gpios = <0x3d 0x05 0x01>;
			linux,code = <0x67>;
			wakeup-source;
		};

		down {
			label = "Down";
			gpios = <0x3d 0x06 0x01>;
			linux,code = <0x6c>;
			wakeup-source;
		};

		home {
			label = "Home";
			gpios = <0x3d 0x04 0x01>;
			linux,code = <0x66>;
			wakeup-source;
		};

		back {
			label = "Back";
			gpios = <0x3d 0x07 0x01>;
			linux,code = <0x9e>;
			wakeup-source;
		};
	};

	gpio-leds {
		compatible = "gpio-leds";
		pinctrl-names = "default";
		pinctrl-0 = <0x7f>;
		status = "okay";

		emmc {
			label = "eMMC";
			gpios = <0x2a 0x12 0x00>;
			linux,default-trigger = "mmc2";
		};
	};

	pcie0-refclk {
		compatible = "fixed-clock";
		#clock-cells = <0x00>;
		clock-frequency = <0x5f5e100>;
		phandle = <0x6c>;
	};

	regulator-usdhc2 {
		compatible = "regulator-fixed";
		pinctrl-names = "default";
		pinctrl-0 = <0x80>;
		regulator-name = "VSD_3V3";
		regulator-min-microvolt = <0x325aa0>;
		regulator-max-microvolt = <0x325aa0>;
		gpio = <0x32 0x13 0x00>;
		off-on-delay-us = <0x4e20>;
		enable-active-high;
		phandle = <0x52>;
	};

	can0_osc {
		compatible = "fixed-clock";
		#clock-cells = <0x00>;
		clock-frequency = <0x2625a00>;
		phandle = <0x2c>;
	};

	__symbols__ {
		cpu_pd_wait = "/cpus/idle-states/cpu-pd-wait";
		A53_0 = "/cpus/cpu@0";
		A53_1 = "/cpus/cpu@1";
		A53_2 = "/cpus/cpu@2";
		A53_3 = "/cpus/cpu@3";
		A53_L2 = "/cpus/l2-cache0";
		a53_opp_table = "/opp-table";
		resmem = "/reserved-memory";
		osc_32k = "/clock-osc-32k";
		osc_24m = "/clock-osc-24m";
		clk_ext1 = "/clock-ext1";
		clk_ext2 = "/clock-ext2";
		clk_ext3 = "/clock-ext3";
		clk_ext4 = "/clock-ext4";
		cpu_alert0 = "/thermal-zones/cpu-thermal/trips/trip0";
		cpu_crit0 = "/thermal-zones/cpu-thermal/trips/trip1";
		usbphynop1 = "/usbphynop1";
		usbphynop2 = "/usbphynop2";
		irq_sec_vio = "/caam_secvio";
		soc = "/soc@0";
		caam_sm = "/soc@0/caam-sm@100000";
		aips1 = "/soc@0/bus@30000000";
		spba2 = "/soc@0/bus@30000000/spba-bus@30000000";
		sai1 = "/soc@0/bus@30000000/spba-bus@30000000/sai@30010000";
		sai2 = "/soc@0/bus@30000000/spba-bus@30000000/sai@30020000";
		sai3 = "/soc@0/bus@30000000/spba-bus@30000000/sai@30030000";
		sai5 = "/soc@0/bus@30000000/spba-bus@30000000/sai@30050000";
		sai6 = "/soc@0/bus@30000000/spba-bus@30000000/sai@30060000";
		micfil = "/soc@0/bus@30000000/spba-bus@30000000/audio-controller@30080000";
		spdif1 = "/soc@0/bus@30000000/spba-bus@30000000/spdif@30090000";
		gpio1 = "/soc@0/bus@30000000/gpio@30200000";
		gpio2 = "/soc@0/bus@30000000/gpio@30210000";
		gpio3 = "/soc@0/bus@30000000/gpio@30220000";
		gpio4 = "/soc@0/bus@30000000/gpio@30230000";
		gpio5 = "/soc@0/bus@30000000/gpio@30240000";
		tmu = "/soc@0/bus@30000000/tmu@30260000";
		wdog1 = "/soc@0/bus@30000000/watchdog@30280000";
		wdog2 = "/soc@0/bus@30000000/watchdog@30290000";
		wdog3 = "/soc@0/bus@30000000/watchdog@302a0000";
		sdma2 = "/soc@0/bus@30000000/dma-controller@302c0000";
		sdma3 = "/soc@0/bus@30000000/dma-controller@302b0000";
		iomuxc = "/soc@0/bus@30000000/pinctrl@30330000";
		pinctrl_fec1 = "/soc@0/bus@30000000/pinctrl@30330000/fec1grp";
		pinctrl_fec1_sleep = "/soc@0/bus@30000000/pinctrl@30330000/fec1grpsleep";
		pinctrl_i2c1 = "/soc@0/bus@30000000/pinctrl@30330000/i2c1grp";
		pinctrl_tpm_reset = "/soc@0/bus@30000000/pinctrl@30330000/tpm-resetgrp";
		pinctrl_i2c3 = "/soc@0/bus@30000000/pinctrl@30330000/i2c3grp";
		pinctrl_i2c1_gpio = "/soc@0/bus@30000000/pinctrl@30330000/i2c1grp-gpio";
		pinctrl_i2c3_gpio = "/soc@0/bus@30000000/pinctrl@30330000/i2c3grp-gpio";
		pinctrl_lvds = "/soc@0/bus@30000000/pinctrl@30330000/lvdsgrp";
		pinctrl_pmic = "/soc@0/bus@30000000/pinctrl@30330000/pmicgrp";
		pinctrl_reg_eth_phy = "/soc@0/bus@30000000/pinctrl@30330000/regethphy";
		pinctrl_sai3 = "/soc@0/bus@30000000/pinctrl@30330000/sai3grp";
		pinctrl_spdif1 = "/soc@0/bus@30000000/pinctrl@30330000/spdif1grp";
		pinctrl_uart4 = "/soc@0/bus@30000000/pinctrl@30330000/uart4grp";
		pinctrl_usdhc1 = "/soc@0/bus@30000000/pinctrl@30330000/usdhc1grp";
		pinctrl_usdhc1_100mhz = "/soc@0/bus@30000000/pinctrl@30330000/usdhc1grp100mhz";
		pinctrl_usdhc1_200mhz = "/soc@0/bus@30000000/pinctrl@30330000/usdhc1grp200mhz";
		pinctrl_usdhc3 = "/soc@0/bus@30000000/pinctrl@30330000/usdhc3grp";
		pinctrl_usdhc3_100mhz = "/soc@0/bus@30000000/pinctrl@30330000/usdhc3grp100mhz";
		pinctrl_usdhc3_200mhz = "/soc@0/bus@30000000/pinctrl@30330000/usdhc3grp200mhz";
		pinctrl_wdog = "/soc@0/bus@30000000/pinctrl@30330000/wdoggrp";
		pinctrl_wifi = "/soc@0/bus@30000000/pinctrl@30330000/wifigrp";
		pinctrl_bt = "/soc@0/bus@30000000/pinctrl@30330000/btgrp";
		pinctrl_flexspi0 = "/soc@0/bus@30000000/pinctrl@30330000/flexspi0grp";
		pinctrl_pdm = "/soc@0/bus@30000000/pinctrl@30330000/pdmgrp";
		pinctrl_i2c2 = "/soc@0/bus@30000000/pinctrl@30330000/i2c2grp";
		pinctrl_i2c2_gpio = "/soc@0/bus@30000000/pinctrl@30330000/i2c2grp-gpio";
		pinctrl_i2c4 = "/soc@0/bus@30000000/pinctrl@30330000/i2c4grp";
		pinctrl_i2c4_gpio = "/soc@0/bus@30000000/pinctrl@30330000/i2c4grp-gpio";
		pinctrl_uart1 = "/soc@0/bus@30000000/pinctrl@30330000/uart1grp";
		pinctrl_uart2 = "/soc@0/bus@30000000/pinctrl@30330000/uart2grp";
		pinctrl_uart3 = "/soc@0/bus@30000000/pinctrl@30330000/uart3grp";
		pinctrl_reg_usdhc2_vmmc = "/soc@0/bus@30000000/pinctrl@30330000/regusdhc2vmmc";
		pinctrl_usdhc2_gpio = "/soc@0/bus@30000000/pinctrl@30330000/usdhc2grpgpio";
		pinctrl_usdhc2 = "/soc@0/bus@30000000/pinctrl@30330000/usdhc2grp";
		pinctrl_usdhc2_100mhz = "/soc@0/bus@30000000/pinctrl@30330000/usdhc2grp100mhz";
		pinctrl_usdhc2_200mhz = "/soc@0/bus@30000000/pinctrl@30330000/usdhc2grp200mhz";
		pinctrl_backlight = "/soc@0/bus@30000000/pinctrl@30330000/backlightgrp";
		pinctrl_captouch = "/soc@0/bus@30000000/pinctrl@30330000/captouchgrp";
		pinctrl_extcon = "/soc@0/bus@30000000/pinctrl@30330000/extcongrp";
		pinctrl_ecspi1 = "/soc@0/bus@30000000/pinctrl@30330000/ecspi1grp";
		pinctrl_can = "/soc@0/bus@30000000/pinctrl@30330000/cangrp";
		pinctrl_leds = "/soc@0/bus@30000000/pinctrl@30330000/ledgrp";
		pinctrl_pca6408 = "/soc@0/bus@30000000/pinctrl@30330000/pca6408grp";
		pinctrl_rtc = "/soc@0/bus@30000000/pinctrl@30330000/rtcgrp";
		gpr = "/soc@0/bus@30000000/syscon@30340000";
		ocotp = "/soc@0/bus@30000000/efuse@30350000";
		imx8mm_uid = "/soc@0/bus@30000000/efuse@30350000/unique-id@4";
		cpu_speed_grade = "/soc@0/bus@30000000/efuse@30350000/speed-grade@10";
		tmu_calib = "/soc@0/bus@30000000/efuse@30350000/calib@3c";
		fec_mac_address = "/soc@0/bus@30000000/efuse@30350000/mac-address@90";
		imx8mm_soc = "/soc@0/bus@30000000/efuse@30350000/imx8mm-soc";
		anatop = "/soc@0/bus@30000000/clock-controller@30360000";
		caam_snvs = "/soc@0/bus@30000000/caam-snvs@30370000";
		snvs = "/soc@0/bus@30000000/snvs@30370000";
		snvs_rtc = "/soc@0/bus@30000000/snvs@30370000/snvs-rtc-lp";
		snvs_pwrkey = "/soc@0/bus@30000000/snvs@30370000/snvs-powerkey";
		snvs_lpgpr = "/soc@0/bus@30000000/snvs@30370000/snvs-lpgpr";
		clk = "/soc@0/bus@30000000/clock-controller@30380000";
		src = "/soc@0/bus@30000000/reset-controller@30390000";
		gpc = "/soc@0/bus@30000000/gpc@303a0000";
		pgc_hsiomix = "/soc@0/bus@30000000/gpc@303a0000/pgc/power-domain@0";
		pgc_pcie = "/soc@0/bus@30000000/gpc@303a0000/pgc/power-domain@1";
		pgc_otg1 = "/soc@0/bus@30000000/gpc@303a0000/pgc/power-domain@2";
		pgc_otg2 = "/soc@0/bus@30000000/gpc@303a0000/pgc/power-domain@3";
		pgc_gpumix = "/soc@0/bus@30000000/gpc@303a0000/pgc/power-domain@4";
		pgc_gpu = "/soc@0/bus@30000000/gpc@303a0000/pgc/power-domain@5";
		pgc_vpumix = "/soc@0/bus@30000000/gpc@303a0000/pgc/power-domain@6";
		pgc_vpu_g1 = "/soc@0/bus@30000000/gpc@303a0000/pgc/power-domain@7";
		pgc_vpu_g2 = "/soc@0/bus@30000000/gpc@303a0000/pgc/power-domain@8";
		pgc_vpu_h1 = "/soc@0/bus@30000000/gpc@303a0000/pgc/power-domain@9";
		pgc_dispmix = "/soc@0/bus@30000000/gpc@303a0000/pgc/power-domain@10";
		pgc_mipi = "/soc@0/bus@30000000/gpc@303a0000/pgc/power-domain@11";
		aips2 = "/soc@0/bus@30400000";
		pwm1 = "/soc@0/bus@30400000/pwm@30660000";
		pwm2 = "/soc@0/bus@30400000/pwm@30670000";
		pwm3 = "/soc@0/bus@30400000/pwm@30680000";
		pwm4 = "/soc@0/bus@30400000/pwm@30690000";
		system_counter = "/soc@0/bus@30400000/timer@306a0000";
		aips3 = "/soc@0/bus@30800000";
		spba1 = "/soc@0/bus@30800000/spba-bus@30800000";
		ecspi1 = "/soc@0/bus@30800000/spba-bus@30800000/spi@30820000";
		can0 = "/soc@0/bus@30800000/spba-bus@30800000/spi@30820000/can@1";
		ecspi2 = "/soc@0/bus@30800000/spba-bus@30800000/spi@30830000";
		ecspi3 = "/soc@0/bus@30800000/spba-bus@30800000/spi@30840000";
		uart1 = "/soc@0/bus@30800000/spba-bus@30800000/serial@30860000";
		uart3 = "/soc@0/bus@30800000/spba-bus@30800000/serial@30880000";
		uart2 = "/soc@0/bus@30800000/spba-bus@30800000/serial@30890000";
		crypto = "/soc@0/bus@30800000/crypto@30900000";
		sec_jr0 = "/soc@0/bus@30800000/crypto@30900000/jr@1000";
		sec_jr1 = "/soc@0/bus@30800000/crypto@30900000/jr@2000";
		sec_jr2 = "/soc@0/bus@30800000/crypto@30900000/jr@3000";
		i2c1 = "/soc@0/bus@30800000/i2c@30a20000";
		dsi_lvds_bridge = "/soc@0/bus@30800000/i2c@30a20000/sn65dsi84@2c";
		bridge_in_dsi = "/soc@0/bus@30800000/i2c@30a20000/sn65dsi84@2c/ports/port@0/endpoint";
		bridge_out_panel = "/soc@0/bus@30800000/i2c@30a20000/sn65dsi84@2c/ports/port@2/endpoint";
		buck1_reg = "/soc@0/bus@30800000/i2c@30a20000/pmic@4b/regulators/BUCK1";
		buck2_reg = "/soc@0/bus@30800000/i2c@30a20000/pmic@4b/regulators/BUCK2";
		buck3_reg = "/soc@0/bus@30800000/i2c@30a20000/pmic@4b/regulators/BUCK3";
		buck4_reg = "/soc@0/bus@30800000/i2c@30a20000/pmic@4b/regulators/BUCK4";
		buck5_reg = "/soc@0/bus@30800000/i2c@30a20000/pmic@4b/regulators/BUCK5";
		buck6_reg = "/soc@0/bus@30800000/i2c@30a20000/pmic@4b/regulators/BUCK6";
		ldo1_reg = "/soc@0/bus@30800000/i2c@30a20000/pmic@4b/regulators/LDO1";
		ldo2_reg = "/soc@0/bus@30800000/i2c@30a20000/pmic@4b/regulators/LDO2";
		ldo3_reg = "/soc@0/bus@30800000/i2c@30a20000/pmic@4b/regulators/LDO3";
		ldo4_reg = "/soc@0/bus@30800000/i2c@30a20000/pmic@4b/regulators/LDO4";
		ldo5_reg = "/soc@0/bus@30800000/i2c@30a20000/pmic@4b/regulators/LDO5";
		ldo6_reg = "/soc@0/bus@30800000/i2c@30a20000/pmic@4b/regulators/LDO6";
		i2c2 = "/soc@0/bus@30800000/i2c@30a30000";
		extcon_ptn5150 = "/soc@0/bus@30800000/i2c@30a30000/typec@3d";
		ft5x06_ts = "/soc@0/bus@30800000/i2c@30a30000/ft5x06_ts@38";
		ov5640_mipi1 = "/soc@0/bus@30800000/i2c@30a30000/ov5640_mipi1@3c";
		ov5640_mipi1_ep = "/soc@0/bus@30800000/i2c@30a30000/ov5640_mipi1@3c/port/endpoint";
		i2c3 = "/soc@0/bus@30800000/i2c@30a40000";
		wm8904 = "/soc@0/bus@30800000/i2c@30a40000/audio-codec@1a";
		i2c4 = "/soc@0/bus@30800000/i2c@30a50000";
		pca6408_1 = "/soc@0/bus@30800000/i2c@30a50000/gpio@20";
		pca6408_2 = "/soc@0/bus@30800000/i2c@30a50000/gpio@21";
		uart4 = "/soc@0/bus@30800000/serial@30a60000";
		bluetooth_iw61x = "/soc@0/bus@30800000/serial@30a60000/bluetooth_iw61x";
		mu = "/soc@0/bus@30800000/mailbox@30aa0000";
		usdhc1 = "/soc@0/bus@30800000/mmc@30b40000";
		usdhc2 = "/soc@0/bus@30800000/mmc@30b50000";
		usdhc3 = "/soc@0/bus@30800000/mmc@30b60000";
		flexspi = "/soc@0/bus@30800000/spi@30bb0000";
		sdma1 = "/soc@0/bus@30800000/dma-controller@30bd0000";
		fec1 = "/soc@0/bus@30800000/ethernet@30be0000";
		ethphy0 = "/soc@0/bus@30800000/ethernet@30be0000/mdio/ethernet-phy@0";
		vddio = "/soc@0/bus@30800000/ethernet@30be0000/mdio/ethernet-phy@0/vddio-regulator";
		aips4 = "/soc@0/bus@32c00000";
		lcdif = "/soc@0/bus@32c00000/lcdif@32e00000";
		lcdif_disp0 = "/soc@0/bus@32c00000/lcdif@32e00000/port";
		lcdif_to_dsim = "/soc@0/bus@32c00000/lcdif@32e00000/port/endpoint";
		mipi_dsi = "/soc@0/bus@32c00000/mipi_dsi@32e10000";
		dsim_from_lcdif = "/soc@0/bus@32c00000/mipi_dsi@32e10000/port@0/endpoint";
		mipi_dsi_out = "/soc@0/bus@32c00000/mipi_dsi@32e10000/port@1/endpoint";
		csi1_bridge = "/soc@0/bus@32c00000/csi1_bridge@32e20000";
		csi1_ep = "/soc@0/bus@32c00000/csi1_bridge@32e20000/port/endpoint";
		mipi_csi_1 = "/soc@0/bus@32c00000/mipi_csi@32e30000";
		mipi1_sensor_ep = "/soc@0/bus@32c00000/mipi_csi@32e30000/port/endpoint@1";
		csi1_mipi_ep = "/soc@0/bus@32c00000/mipi_csi@32e30000/port/endpoint@2";
		disp_blk_ctrl = "/soc@0/bus@32c00000/blk-ctrl@32e28000";
		usbotg1 = "/soc@0/bus@32c00000/usb@32e40000";
		usb1_drd_sw = "/soc@0/bus@32c00000/usb@32e40000/port/endpoint";
		usbmisc1 = "/soc@0/bus@32c00000/usbmisc@32e40200";
		usbotg2 = "/soc@0/bus@32c00000/usb@32e50000";
		usbmisc2 = "/soc@0/bus@32c00000/usbmisc@32e50200";
		pcie_phy = "/soc@0/bus@32c00000/pcie-phy@32f00000";
		dma_apbh = "/soc@0/dma-controller@33000000";
		gpmi = "/soc@0/nand-controller@33002000";
		pcie0 = "/soc@0/pcie@33800000";
		pcie0_ep = "/soc@0/pcie-ep@33800000";
		vpu_blk_ctrl = "/soc@0/blk-ctrl@38330000";
		gic = "/soc@0/interrupt-controller@38800000";
		vpu_h1 = "/vpu_h1@38320000";
		vpu_g1 = "/vpu_g1@38300000";
		vpu_g2 = "/vpu_g2@38310000";
		vpu_v4l2 = "/vpu_v4l2";
		gpu = "/gpu@38000000";
		iw612_pwrseq = "/iw612_pwrseq";
		panel_lvds = "/panel-lvds";
		panel_in_bridge = "/panel-lvds/port/endpoint";
		reg_audio = "/audio_vdd";
		reg_eth_phy = "/regulator-eth-phy";
		dailink_master = "/sound-wm8904/simple-audio-card,codec";
		backlight = "/backlight";
		pcie0_refclk = "/pcie0-refclk";
		reg_usdhc2_vmmc = "/regulator-usdhc2";
		can0_osc = "/can0_osc";
		pinctrl_pps = "/soc@0/bus@30000000/pinctrl@30330000/ppsgrp";
		pps = "/pps";
	};
};
